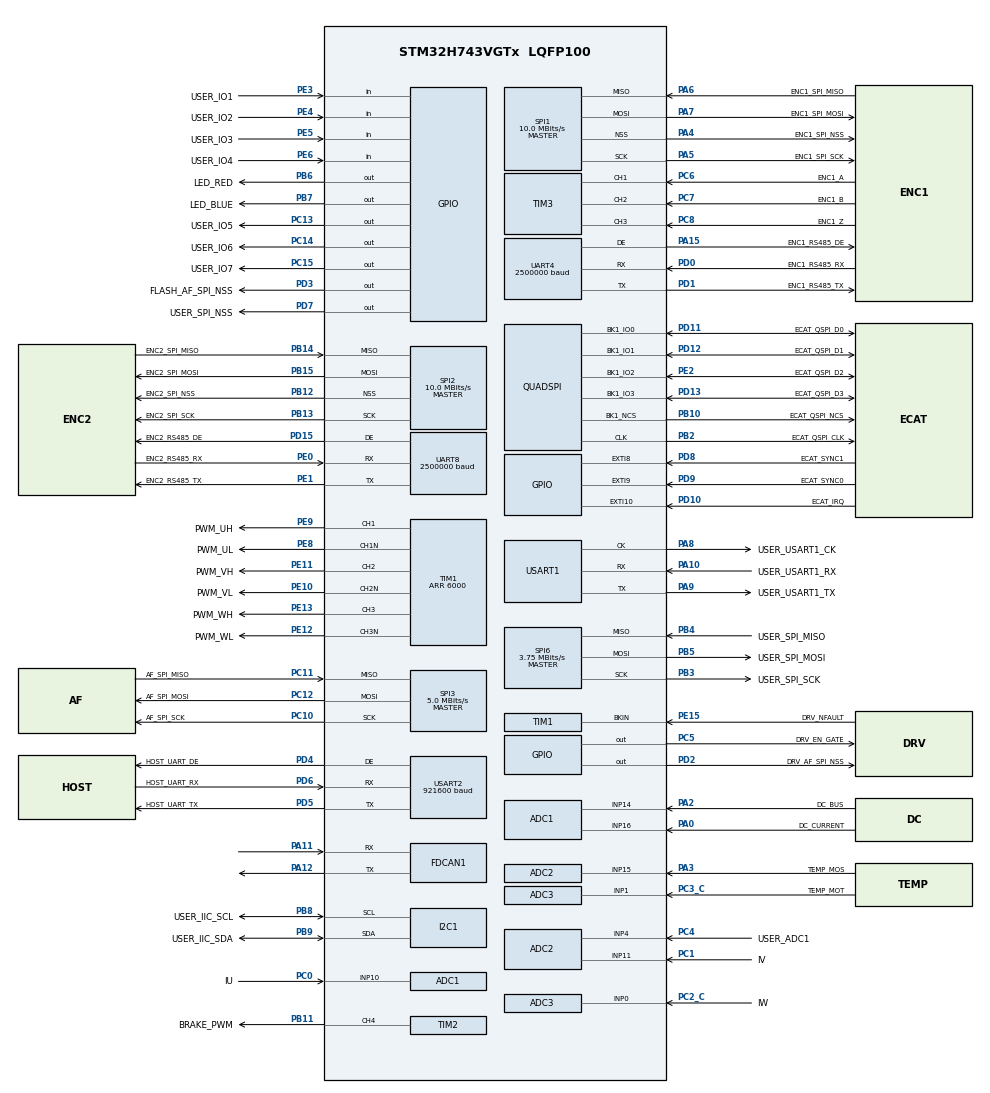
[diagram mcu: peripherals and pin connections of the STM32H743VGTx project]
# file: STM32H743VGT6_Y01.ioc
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ADC1.Channel-3\#ChannelRegularConversion=ADC_CHANNEL_14
ADC1.Channel-5\#ChannelRegularConversion=ADC_CHANNEL_16
ADC1.ClockPrescaler=ADC_CLOCK_ASYNC_DIV1
ADC1.ContinuousConvMode=ENABLE
ADC1.ConversionDataManagement=ADC_CONVERSIONDATA_DMA_CIRCULAR
ADC1.DiscontinuousConvMode=DISABLE
ADC1.EnableInjectedConversion=ENABLE
ADC1.ExternalTrigInjecConv=ADC_EXTERNALTRIGINJEC_T1_TRGO
ADC1.InjNumberOfConversion=1
ADC1.InjectedChannel-4\#ChannelInjectedConversion=ADC_CHANNEL_10
ADC1.InjectedOffsetNumber-4\#ChannelInjectedConversion=ADC_OFFSET_NONE
ADC1.InjectedOffsetSaturation-4\#ChannelInjectedConversion=DISABLE
ADC1.InjectedOffsetSignedSaturation-4\#ChannelInjectedConversion=DISABLE
ADC1.InjectedRank-4\#ChannelInjectedConversion=1
ADC1.InjectedSamplingTime-4\#ChannelInjectedConversion=ADC_SAMPLETIME_2CYCLES_5
ADC1.NbrOfConversion=2
ADC1.NbrOfConversionFlag=1
ADC1.NbrOfDiscConversion=2
ADC1.OffsetNumber-3\#ChannelRegularConversion=ADC_OFFSET_NONE
ADC1.OffsetNumber-5\#ChannelRegularConversion=ADC_OFFSET_NONE
ADC1.OffsetSignedSaturation-3\#ChannelRegularConversion=DISABLE
ADC1.OffsetSignedSaturation-5\#ChannelRegularConversion=DISABLE
ADC1.Rank-3\#ChannelRegularConversion=1
ADC1.Rank-5\#ChannelRegularConversion=2
ADC1.SamplingTime-3\#ChannelRegularConversion=ADC_SAMPLETIME_2CYCLES_5
ADC1.SamplingTime-5\#ChannelRegularConversion=ADC_SAMPLETIME_2CYCLES_5
ADC1.master=1
ADC2.Channel-2\#ChannelRegularConversion=ADC_CHANNEL_15
ADC2.Channel-3\#ChannelRegularConversion=ADC_CHANNEL_4
ADC2.ContinuousConvMode=ENABLE
ADC2.ConversionDataManagement=ADC_CONVERSIONDATA_DMA_CIRCULAR
ADC2.DiscontinuousConvMode=DISABLE
ADC2.EnableInjectedConversion=ENABLE
ADC2.ExternalTrigInjecConv=ADC_EXTERNALTRIGINJEC_T1_TRGO
ADC2.InjNumberOfConversion=1
ADC2.InjectedChannel-4\#ChannelInjectedConversion=ADC_CHANNEL_11
ADC2.InjectedOffsetNumber-4\#ChannelInjectedConversion=ADC_OFFSET_NONE
ADC2.InjectedOffsetSaturation-4\#ChannelInjectedConversion=DISABLE
ADC2.InjectedOffsetSignedSaturation-4\#ChannelInjectedConversion=DISABLE
ADC2.InjectedRank-4\#ChannelInjectedConversion=1
ADC2.InjectedSamplingTime-4\#ChannelInjectedConversion=ADC_SAMPLETIME_2CYCLES_5
ADC2.NbrOfConversion=2
ADC2.NbrOfConversionFlag=1
ADC2.NbrOfDiscConversion=2
ADC2.OffsetNumber-2\#ChannelRegularConversion=ADC_OFFSET_NONE
ADC2.OffsetNumber-3\#ChannelRegularConversion=ADC_OFFSET_NONE
ADC2.OffsetSignedSaturation-2\#ChannelRegularConversion=DISABLE
ADC2.OffsetSignedSaturation-3\#ChannelRegularConversion=DISABLE
ADC2.Rank-2\#ChannelRegularConversion=1
ADC2.Rank-3\#ChannelRegularConversion=2
ADC2.SamplingTime-2\#ChannelRegularConversion=ADC_SAMPLETIME_387CYCLES_5
ADC2.SamplingTime-3\#ChannelRegularConversion=ADC_SAMPLETIME_2CYCLES_5
ADC3.Channel-3\#ChannelRegularConversion=ADC_CHANNEL_TEMPSENSOR
ADC3.Channel-4\#ChannelRegularConversion=ADC_CHANNEL_1
ADC3.ClockPrescaler=ADC_CLOCK_ASYNC_DIV1
ADC3.ContinuousConvMode=ENABLE
ADC3.ConversionDataManagement=ADC_CONVERSIONDATA_DMA_CIRCULAR
ADC3.DiscontinuousConvMode=DISABLE
ADC3.EnableInjectedConversion=ENABLE
ADC3.ExternalTrigInjecConv=ADC_EXTERNALTRIGINJEC_T1_TRGO
ADC3.InjNumberOfConversion=1
ADC3.InjectedChannel-5\#ChannelInjectedConversion=ADC_CHANNEL_0
ADC3.InjectedOffsetNumber-5\#ChannelInjectedConversion=ADC_OFFSET_NONE
ADC3.InjectedOffsetSaturation-5\#ChannelInjectedConversion=DISABLE
ADC3.InjectedOffsetSignedSaturation-5\#ChannelInjectedConversion=DISABLE
ADC3.InjectedRank-5\#ChannelInjectedConversion=1
ADC3.InjectedSamplingTime-5\#ChannelInjectedConversion=ADC_SAMPLETIME_2CYCLES_5
ADC3.NbrOfConversion=2
ADC3.NbrOfConversionFlag=1
ADC3.NbrOfDiscConversion=2
ADC3.OffsetNumber-3\#ChannelRegularConversion=ADC_OFFSET_NONE
ADC3.OffsetNumber-4\#ChannelRegularConversion=ADC_OFFSET_NONE
ADC3.OffsetSignedSaturation-3\#ChannelRegularConversion=DISABLE
ADC3.OffsetSignedSaturation-4\#ChannelRegularConversion=DISABLE
ADC3.Rank-3\#ChannelRegularConversion=1
ADC3.Rank-4\#ChannelRegularConversion=2
ADC3.SamplingTime-3\#ChannelRegularConversion=ADC_SAMPLETIME_810CYCLES_5
ADC3.SamplingTime-4\#ChannelRegularConversion=ADC_SAMPLETIME_387CYCLES_5
CORTEX_M7.default_mode_Activation=0
CRC.InputDataFormat=CRC_INPUTDATA_FORMAT_WORDS
Dma.ADC1.10.Direction=DMA_PERIPH_TO_MEMORY
Dma.ADC1.10.EventEnable=DISABLE
Dma.ADC1.10.FIFOMode=DMA_FIFOMODE_DISABLE
Dma.ADC1.10.Instance=DMA2_Stream4
Dma.ADC1.10.MemDataAlignment=DMA_MDATAALIGN_HALFWORD
Dma.ADC1.10.MemInc=DMA_MINC_ENABLE
Dma.ADC1.10.Mode=DMA_CIRCULAR
Dma.ADC1.10.PeriphDataAlignment=DMA_PDATAALIGN_HALFWORD
Dma.ADC1.10.PeriphInc=DMA_PINC_DISABLE
Dma.ADC1.10.Polarity=HAL_DMAMUX_REQ_GEN_RISING
Dma.ADC1.10.Priority=DMA_PRIORITY_MEDIUM
Dma.ADC1.10.RequestNumber=1
Dma.ADC1.10.SignalID=NONE
Dma.ADC1.10.SyncEnable=DISABLE
Dma.ADC1.10.SyncPolarity=HAL_DMAMUX_SYNC_NO_EVENT
Dma.ADC1.10.SyncRequestNumber=1
Dma.ADC1.10.SyncSignalID=NONE
Dma.ADC2.11.Direction=DMA_PERIPH_TO_MEMORY
Dma.ADC2.11.EventEnable=DISABLE
Dma.ADC2.11.FIFOMode=DMA_FIFOMODE_DISABLE
Dma.ADC2.11.Instance=DMA2_Stream5
Dma.ADC2.11.MemDataAlignment=DMA_MDATAALIGN_HALFWORD
Dma.ADC2.11.MemInc=DMA_MINC_ENABLE
Dma.ADC2.11.Mode=DMA_CIRCULAR
Dma.ADC2.11.PeriphDataAlignment=DMA_PDATAALIGN_HALFWORD
Dma.ADC2.11.PeriphInc=DMA_PINC_DISABLE
Dma.ADC2.11.Polarity=HAL_DMAMUX_REQ_GEN_RISING
Dma.ADC2.11.Priority=DMA_PRIORITY_MEDIUM
Dma.ADC2.11.RequestNumber=1
Dma.ADC2.11.SignalID=NONE
Dma.ADC2.11.SyncEnable=DISABLE
Dma.ADC2.11.SyncPolarity=HAL_DMAMUX_SYNC_NO_EVENT
Dma.ADC2.11.SyncRequestNumber=1
Dma.ADC2.11.SyncSignalID=NONE
Dma.ADC3.12.Direction=DMA_PERIPH_TO_MEMORY
Dma.ADC3.12.EventEnable=DISABLE
Dma.ADC3.12.FIFOMode=DMA_FIFOMODE_DISABLE
Dma.ADC3.12.Instance=DMA2_Stream6
Dma.ADC3.12.MemDataAlignment=DMA_MDATAALIGN_HALFWORD
Dma.ADC3.12.MemInc=DMA_MINC_ENABLE
Dma.ADC3.12.Mode=DMA_CIRCULAR
Dma.ADC3.12.PeriphDataAlignment=DMA_PDATAALIGN_HALFWORD
Dma.ADC3.12.PeriphInc=DMA_PINC_DISABLE
Dma.ADC3.12.Polarity=HAL_DMAMUX_REQ_GEN_RISING
Dma.ADC3.12.Priority=DMA_PRIORITY_MEDIUM
Dma.ADC3.12.RequestNumber=1
Dma.ADC3.12.SignalID=NONE
Dma.ADC3.12.SyncEnable=DISABLE
Dma.ADC3.12.SyncPolarity=HAL_DMAMUX_SYNC_NO_EVENT
Dma.ADC3.12.SyncRequestNumber=1
Dma.ADC3.12.SyncSignalID=NONE
Dma.Request0=UART4_RX
Dma.Request1=UART4_TX
Dma.Request10=ADC1
Dma.Request11=ADC2
Dma.Request12=ADC3
Dma.Request2=SPI1_RX
Dma.Request3=SPI1_TX
Dma.Request4=UART8_RX
Dma.Request5=UART8_TX
Dma.Request6=SPI2_RX
Dma.Request7=SPI2_TX
Dma.Request8=USART2_RX
Dma.Request9=USART2_TX
Dma.SPI1_RX.2.Direction=DMA_PERIPH_TO_MEMORY
Dma.SPI1_RX.2.EventEnable=DISABLE
Dma.SPI1_RX.2.FIFOMode=DMA_FIFOMODE_DISABLE
Dma.SPI1_RX.2.Instance=DMA1_Stream2
Dma.SPI1_RX.2.MemDataAlignment=DMA_MDATAALIGN_BYTE
Dma.SPI1_RX.2.MemInc=DMA_MINC_ENABLE
Dma.SPI1_RX.2.Mode=DMA_NORMAL
Dma.SPI1_RX.2.PeriphDataAlignment=DMA_PDATAALIGN_BYTE
Dma.SPI1_RX.2.PeriphInc=DMA_PINC_DISABLE
Dma.SPI1_RX.2.Polarity=HAL_DMAMUX_REQ_GEN_RISING
Dma.SPI1_RX.2.Priority=DMA_PRIORITY_VERY_HIGH
Dma.SPI1_RX.2.RequestNumber=1
Dma.SPI1_RX.2.SignalID=NONE
Dma.SPI1_RX.2.SyncEnable=DISABLE
Dma.SPI1_RX.2.SyncPolarity=HAL_DMAMUX_SYNC_NO_EVENT
Dma.SPI1_RX.2.SyncRequestNumber=1
Dma.SPI1_RX.2.SyncSignalID=NONE
Dma.SPI1_TX.3.Direction=DMA_MEMORY_TO_PERIPH
Dma.SPI1_TX.3.EventEnable=DISABLE
Dma.SPI1_TX.3.FIFOMode=DMA_FIFOMODE_DISABLE
Dma.SPI1_TX.3.Instance=DMA1_Stream3
Dma.SPI1_TX.3.MemDataAlignment=DMA_MDATAALIGN_BYTE
Dma.SPI1_TX.3.MemInc=DMA_MINC_ENABLE
Dma.SPI1_TX.3.Mode=DMA_NORMAL
Dma.SPI1_TX.3.PeriphDataAlignment=DMA_PDATAALIGN_BYTE
Dma.SPI1_TX.3.PeriphInc=DMA_PINC_DISABLE
Dma.SPI1_TX.3.Polarity=HAL_DMAMUX_REQ_GEN_RISING
Dma.SPI1_TX.3.Priority=DMA_PRIORITY_VERY_HIGH
Dma.SPI1_TX.3.RequestNumber=1
Dma.SPI1_TX.3.SignalID=NONE
Dma.SPI1_TX.3.SyncEnable=DISABLE
Dma.SPI1_TX.3.SyncPolarity=HAL_DMAMUX_SYNC_NO_EVENT
Dma.SPI1_TX.3.SyncRequestNumber=1
Dma.SPI1_TX.3.SyncSignalID=NONE
Dma.SPI2_RX.6.Direction=DMA_PERIPH_TO_MEMORY
Dma.SPI2_RX.6.EventEnable=DISABLE
Dma.SPI2_RX.6.FIFOMode=DMA_FIFOMODE_DISABLE
Dma.SPI2_RX.6.Instance=DMA2_Stream2
Dma.SPI2_RX.6.MemDataAlignment=DMA_MDATAALIGN_BYTE
Dma.SPI2_RX.6.MemInc=DMA_MINC_ENABLE
Dma.SPI2_RX.6.Mode=DMA_NORMAL
Dma.SPI2_RX.6.PeriphDataAlignment=DMA_PDATAALIGN_BYTE
Dma.SPI2_RX.6.PeriphInc=DMA_PINC_DISABLE
Dma.SPI2_RX.6.Polarity=HAL_DMAMUX_REQ_GEN_RISING
Dma.SPI2_RX.6.Priority=DMA_PRIORITY_VERY_HIGH
Dma.SPI2_RX.6.RequestNumber=1
Dma.SPI2_RX.6.SignalID=NONE
Dma.SPI2_RX.6.SyncEnable=DISABLE
Dma.SPI2_RX.6.SyncPolarity=HAL_DMAMUX_SYNC_NO_EVENT
Dma.SPI2_RX.6.SyncRequestNumber=1
Dma.SPI2_RX.6.SyncSignalID=NONE
Dma.SPI2_TX.7.Direction=DMA_MEMORY_TO_PERIPH
Dma.SPI2_TX.7.EventEnable=DISABLE
Dma.SPI2_TX.7.FIFOMode=DMA_FIFOMODE_DISABLE
Dma.SPI2_TX.7.Instance=DMA2_Stream3
Dma.SPI2_TX.7.MemDataAlignment=DMA_MDATAALIGN_BYTE
Dma.SPI2_TX.7.MemInc=DMA_MINC_ENABLE
Dma.SPI2_TX.7.Mode=DMA_NORMAL
Dma.SPI2_TX.7.PeriphDataAlignment=DMA_PDATAALIGN_BYTE
Dma.SPI2_TX.7.PeriphInc=DMA_PINC_DISABLE
Dma.SPI2_TX.7.Polarity=HAL_DMAMUX_REQ_GEN_RISING
Dma.SPI2_TX.7.Priority=DMA_PRIORITY_VERY_HIGH
Dma.SPI2_TX.7.RequestNumber=1
Dma.SPI2_TX.7.SignalID=NONE
Dma.SPI2_TX.7.SyncEnable=DISABLE
Dma.SPI2_TX.7.SyncPolarity=HAL_DMAMUX_SYNC_NO_EVENT
Dma.SPI2_TX.7.SyncRequestNumber=1
Dma.SPI2_TX.7.SyncSignalID=NONE
Dma.UART4_RX.0.Direction=DMA_PERIPH_TO_MEMORY
Dma.UART4_RX.0.EventEnable=DISABLE
Dma.UART4_RX.0.FIFOMode=DMA_FIFOMODE_DISABLE
Dma.UART4_RX.0.Instance=DMA1_Stream0
Dma.UART4_RX.0.MemDataAlignment=DMA_MDATAALIGN_BYTE
Dma.UART4_RX.0.MemInc=DMA_MINC_ENABLE
Dma.UART4_RX.0.Mode=DMA_NORMAL
Dma.UART4_RX.0.PeriphDataAlignment=DMA_PDATAALIGN_BYTE
Dma.UART4_RX.0.PeriphInc=DMA_PINC_DISABLE
Dma.UART4_RX.0.Polarity=HAL_DMAMUX_REQ_GEN_RISING
Dma.UART4_RX.0.Priority=DMA_PRIORITY_VERY_HIGH
Dma.UART4_RX.0.RequestNumber=1
Dma.UART4_RX.0.SignalID=NONE
Dma.UART4_RX.0.SyncEnable=DISABLE
Dma.UART4_RX.0.SyncPolarity=HAL_DMAMUX_SYNC_NO_EVENT
Dma.UART4_RX.0.SyncRequestNumber=1
Dma.UART4_RX.0.SyncSignalID=NONE
Dma.UART4_TX.1.Direction=DMA_MEMORY_TO_PERIPH
Dma.UART4_TX.1.EventEnable=DISABLE
Dma.UART4_TX.1.FIFOMode=DMA_FIFOMODE_DISABLE
Dma.UART4_TX.1.Instance=DMA1_Stream1
Dma.UART4_TX.1.MemDataAlignment=DMA_MDATAALIGN_BYTE
Dma.UART4_TX.1.MemInc=DMA_MINC_ENABLE
Dma.UART4_TX.1.Mode=DMA_NORMAL
Dma.UART4_TX.1.PeriphDataAlignment=DMA_PDATAALIGN_BYTE
Dma.UART4_TX.1.PeriphInc=DMA_PINC_DISABLE
Dma.UART4_TX.1.Polarity=HAL_DMAMUX_REQ_GEN_RISING
Dma.UART4_TX.1.Priority=DMA_PRIORITY_VERY_HIGH
Dma.UART4_TX.1.RequestNumber=1
Dma.UART4_TX.1.SignalID=NONE
Dma.UART4_TX.1.SyncEnable=DISABLE
Dma.UART4_TX.1.SyncPolarity=HAL_DMAMUX_SYNC_NO_EVENT
Dma.UART4_TX.1.SyncRequestNumber=1
Dma.UART4_TX.1.SyncSignalID=NONE
Dma.UART8_RX.4.Direction=DMA_PERIPH_TO_MEMORY
Dma.UART8_RX.4.EventEnable=DISABLE
Dma.UART8_RX.4.FIFOMode=DMA_FIFOMODE_DISABLE
Dma.UART8_RX.4.Instance=DMA2_Stream0
Dma.UART8_RX.4.MemDataAlignment=DMA_MDATAALIGN_BYTE
Dma.UART8_RX.4.MemInc=DMA_MINC_ENABLE
Dma.UART8_RX.4.Mode=DMA_NORMAL
Dma.UART8_RX.4.PeriphDataAlignment=DMA_PDATAALIGN_BYTE
Dma.UART8_RX.4.PeriphInc=DMA_PINC_DISABLE
Dma.UART8_RX.4.Polarity=HAL_DMAMUX_REQ_GEN_RISING
Dma.UART8_RX.4.Priority=DMA_PRIORITY_VERY_HIGH
Dma.UART8_RX.4.RequestNumber=1
Dma.UART8_RX.4.SignalID=NONE
Dma.UART8_RX.4.SyncEnable=DISABLE
Dma.UART8_RX.4.SyncPolarity=HAL_DMAMUX_SYNC_NO_EVENT
Dma.UART8_RX.4.SyncRequestNumber=1
Dma.UART8_RX.4.SyncSignalID=NONE
Dma.UART8_TX.5.Direction=DMA_MEMORY_TO_PERIPH
Dma.UART8_TX.5.EventEnable=DISABLE
Dma.UART8_TX.5.FIFOMode=DMA_FIFOMODE_DISABLE
Dma.UART8_TX.5.Instance=DMA2_Stream1
Dma.UART8_TX.5.MemDataAlignment=DMA_MDATAALIGN_BYTE
Dma.UART8_TX.5.MemInc=DMA_MINC_ENABLE
Dma.UART8_TX.5.Mode=DMA_NORMAL
Dma.UART8_TX.5.PeriphDataAlignment=DMA_PDATAALIGN_BYTE
Dma.UART8_TX.5.PeriphInc=DMA_PINC_DISABLE
Dma.UART8_TX.5.Polarity=HAL_DMAMUX_REQ_GEN_RISING
Dma.UART8_TX.5.Priority=DMA_PRIORITY_VERY_HIGH
Dma.UART8_TX.5.RequestNumber=1
Dma.UART8_TX.5.SignalID=NONE
Dma.UART8_TX.5.SyncEnable=DISABLE
Dma.UART8_TX.5.SyncPolarity=HAL_DMAMUX_SYNC_NO_EVENT
Dma.UART8_TX.5.SyncRequestNumber=1
Dma.UART8_TX.5.SyncSignalID=NONE
Dma.USART2_RX.8.Direction=DMA_PERIPH_TO_MEMORY
Dma.USART2_RX.8.EventEnable=DISABLE
Dma.USART2_RX.8.FIFOMode=DMA_FIFOMODE_DISABLE
Dma.USART2_RX.8.Instance=DMA1_Stream4
Dma.USART2_RX.8.MemDataAlignment=DMA_MDATAALIGN_BYTE
Dma.USART2_RX.8.MemInc=DMA_MINC_ENABLE
Dma.USART2_RX.8.Mode=DMA_NORMAL
Dma.USART2_RX.8.PeriphDataAlignment=DMA_PDATAALIGN_BYTE
Dma.USART2_RX.8.PeriphInc=DMA_PINC_DISABLE
Dma.USART2_RX.8.Polarity=HAL_DMAMUX_REQ_GEN_RISING
Dma.USART2_RX.8.Priority=DMA_PRIORITY_LOW
Dma.USART2_RX.8.RequestNumber=1
Dma.USART2_RX.8.SignalID=NONE
Dma.USART2_RX.8.SyncEnable=DISABLE
Dma.USART2_RX.8.SyncPolarity=HAL_DMAMUX_SYNC_NO_EVENT
Dma.USART2_RX.8.SyncRequestNumber=1
Dma.USART2_RX.8.SyncSignalID=NONE
Dma.USART2_TX.9.Direction=DMA_MEMORY_TO_PERIPH
Dma.USART2_TX.9.EventEnable=DISABLE
Dma.USART2_TX.9.FIFOMode=DMA_FIFOMODE_DISABLE
Dma.USART2_TX.9.Instance=DMA1_Stream5
Dma.USART2_TX.9.MemDataAlignment=DMA_MDATAALIGN_BYTE
Dma.USART2_TX.9.MemInc=DMA_MINC_ENABLE
Dma.USART2_TX.9.Mode=DMA_NORMAL
Dma.USART2_TX.9.PeriphDataAlignment=DMA_PDATAALIGN_BYTE
Dma.USART2_TX.9.PeriphInc=DMA_PINC_DISABLE
Dma.USART2_TX.9.Polarity=HAL_DMAMUX_REQ_GEN_RISING
Dma.USART2_TX.9.Priority=DMA_PRIORITY_LOW
Dma.USART2_TX.9.RequestNumber=1
Dma.USART2_TX.9.SignalID=NONE
Dma.USART2_TX.9.SyncEnable=DISABLE
Dma.USART2_TX.9.SyncPolarity=HAL_DMAMUX_SYNC_NO_EVENT
Dma.USART2_TX.9.SyncRequestNumber=1
Dma.USART2_TX.9.SyncSignalID=NONE
FDCAN1.AutoRetransmission=ENABLE
FDCAN1.CalculateBaudRateNominal=1000000
FDCAN1.CalculateTimeBitNominal=1000
FDCAN1.CalculateTimeQuantumNominal=100.0
FDCAN1.DataPrescaler=8
FDCAN1.DataTimeSeg1=7
FDCAN1.DataTimeSeg2=2
FDCAN1.ExtFiltersNbr=64
FDCAN1.FrameFormat=FDCAN_FRAME_FD_BRS
FDCAN1.NominalPrescaler=8
FDCAN1.NominalSyncJumpWidth=2
FDCAN1.NominalTimeSeg1=7
FDCAN1.ProtocolException=ENABLE
FDCAN1.RxBufferSize=FDCAN_DATA_BYTES_64
FDCAN1.RxBuffersNbr=8
FDCAN1.RxFifo0ElmtSize=FDCAN_DATA_BYTES_64
FDCAN1.RxFifo0ElmtsNbr=32
FDCAN1.RxFifo1ElmtSize=FDCAN_DATA_BYTES_64
FDCAN1.RxFifo1ElmtsNbr=32
FDCAN1.StdFiltersNbr=128
FDCAN1.TransmitPause=ENABLE
FDCAN1.TxElmtSize=FDCAN_DATA_BYTES_64
FDCAN1.TxFifoQueueElmtsNbr=32
I2C1.I2C_Fall_Time=10
I2C1.I2C_Rise_Time=100
I2C1.Speed=100
I2C1.Timing=0x40805E8A
Mcu.Family=STM32H7
Mcu.Name=STM32H743VGTx
Mcu.Package=LQFP100
NVIC.ADC_IRQn=true\:2\:0\:true\:false\:true\:true\:true\:true
NVIC.DMA1_Stream0_IRQn=true\:1\:0\:true\:false\:true\:false\:true\:true
NVIC.DMA1_Stream1_IRQn=true\:1\:0\:true\:false\:true\:false\:true\:true
NVIC.DMA1_Stream2_IRQn=true\:1\:0\:true\:false\:true\:false\:true\:true
NVIC.DMA1_Stream3_IRQn=true\:1\:0\:true\:false\:true\:false\:true\:true
NVIC.DMA1_Stream4_IRQn=true\:7\:0\:true\:false\:true\:false\:true\:true
NVIC.DMA1_Stream5_IRQn=true\:7\:0\:true\:false\:true\:false\:true\:true
NVIC.DMA2_Stream0_IRQn=true\:1\:0\:true\:false\:true\:false\:true\:true
NVIC.DMA2_Stream1_IRQn=true\:1\:0\:true\:false\:true\:false\:true\:true
NVIC.DMA2_Stream2_IRQn=true\:1\:0\:true\:false\:true\:false\:true\:true
NVIC.DMA2_Stream3_IRQn=true\:1\:0\:true\:false\:true\:false\:true\:true
NVIC.EXTI15_10_IRQn=true\:2\:0\:true\:false\:true\:true\:true\:false
NVIC.EXTI9_5_IRQn=true\:1\:0\:true\:false\:true\:true\:true\:false
NVIC.FDCAN1_IT0_IRQn=true\:5\:0\:true\:false\:true\:true\:true\:true
NVIC.FDCAN1_IT1_IRQn=true\:5\:0\:true\:false\:true\:true\:true\:true
NVIC.PriorityGroup=NVIC_PRIORITYGROUP_4
NVIC.SPI1_IRQn=true\:0\:0\:false\:false\:true\:false\:true\:true
NVIC.SPI2_IRQn=true\:0\:0\:false\:false\:true\:false\:true\:true
NVIC.TIM1_BRK_IRQn=true\:0\:0\:false\:false\:true\:true\:true\:true
NVIC.TIM2_IRQn=true\:9\:0\:true\:false\:true\:true\:true\:true
NVIC.TIM3_IRQn=true\:2\:0\:true\:false\:true\:true\:true\:true
NVIC.TIM5_IRQn=true\:3\:0\:true\:false\:false\:true\:true\:true
NVIC.TIM6_DAC_IRQn=true\:4\:0\:true\:false\:true\:true\:true\:true
NVIC.TIM7_IRQn=true\:4\:0\:true\:false\:true\:true\:true\:true
NVIC.TIM8_UP_TIM13_IRQn=true\:5\:0\:true\:false\:true\:true\:true\:true
NVIC.USART2_IRQn=true\:8\:0\:true\:false\:false\:true\:false\:true
PA0.GPIO_Label=DC_CURRENT
PA0.Mode=IN16-Single-Ended
PA0.Signal=ADC1_INP16
PA10.GPIO_Label=USER_USART1_RX
PA10.GPIO_Speed=GPIO_SPEED_FREQ_VERY_HIGH
PA10.Mode=Synchronous
PA10.PinAttribute=Free
PA10.Signal=USART1_RX
PA11.GPIO_Speed=GPIO_SPEED_FREQ_VERY_HIGH
PA11.Mode=FDCAN_Activate
PA11.Signal=FDCAN1_RX
PA12.GPIO_Speed=GPIO_SPEED_FREQ_VERY_HIGH
PA12.Mode=FDCAN_Activate
PA12.Signal=FDCAN1_TX
PA13\ (JTMS/SWDIO).GPIO_Label=SWDIO
PA13\ (JTMS/SWDIO).Mode=Serial_Wire
PA13\ (JTMS/SWDIO).Signal=DEBUG_JTMS-SWDIO
PA14\ (JTCK/SWCLK).GPIO_Label=SWCLK
PA14\ (JTCK/SWCLK).Mode=Serial_Wire
PA14\ (JTCK/SWCLK).Signal=DEBUG_JTCK-SWCLK
PA15\ (JTDI).GPIO_Label=ENC1_RS485_DE
PA15\ (JTDI).GPIO_Speed=GPIO_SPEED_FREQ_VERY_HIGH
PA15\ (JTDI).Mode=Hardware Flow Control (RS485)
PA15\ (JTDI).Signal=UART4_DE
PA2.GPIO_Label=DC_BUS
PA2.Signal=ADCx_INP14
PA3.GPIO_Label=TEMP_MOS
PA3.Signal=ADCx_INP15
PA4.GPIO_Label=ENC1_SPI_NSS
PA4.GPIO_Speed=GPIO_SPEED_FREQ_VERY_HIGH
PA4.Mode=NSS_Signal_Hard_Output
PA4.Signal=SPI1_NSS
PA5.GPIO_Label=ENC1_SPI_SCK
PA5.GPIO_Speed=GPIO_SPEED_FREQ_VERY_HIGH
PA5.Mode=Full_Duplex_Master
PA5.Signal=SPI1_SCK
PA6.GPIO_Label=ENC1_SPI_MISO
PA6.GPIO_Speed=GPIO_SPEED_FREQ_VERY_HIGH
PA6.Mode=Full_Duplex_Master
PA6.Signal=SPI1_MISO
PA7.GPIO_Label=ENC1_SPI_MOSI
PA7.GPIO_Speed=GPIO_SPEED_FREQ_VERY_HIGH
PA7.Mode=Full_Duplex_Master
PA7.Signal=SPI1_MOSI
PA8.GPIO_Label=USER_USART1_CK
PA8.GPIO_Speed=GPIO_SPEED_FREQ_VERY_HIGH
PA8.Mode=Synchronous
PA8.PinAttribute=Free
PA8.Signal=USART1_CK
PA9.GPIO_Label=USER_USART1_TX
PA9.GPIO_Speed=GPIO_SPEED_FREQ_VERY_HIGH
PA9.Mode=Synchronous
PA9.PinAttribute=Free
PA9.Signal=USART1_TX
PB10.GPIO_Label=ECAT_QSPI_NCS
PB10.GPIO_Speed=GPIO_SPEED_FREQ_VERY_HIGH
PB10.Mode=Single Bank 1
PB10.PinAttribute=Free
PB10.Signal=QUADSPI_BK1_NCS
PB11.GPIO_Label=BRAKE_PWM
PB11.GPIO_Speed=GPIO_SPEED_FREQ_VERY_HIGH
PB11.PinAttribute=Free
PB11.Signal=S_TIM2_CH4
PB12.GPIO_Label=ENC2_SPI_NSS
PB12.GPIO_Speed=GPIO_SPEED_FREQ_VERY_HIGH
PB12.Mode=NSS_Signal_Hard_Output
PB12.PinAttribute=Free
PB12.Signal=SPI2_NSS
PB13.GPIO_Label=ENC2_SPI_SCK
PB13.GPIO_Speed=GPIO_SPEED_FREQ_VERY_HIGH
PB13.Mode=Full_Duplex_Master
PB13.PinAttribute=Free
PB13.Signal=SPI2_SCK
PB14.GPIO_Label=ENC2_SPI_MISO
PB14.GPIO_Speed=GPIO_SPEED_FREQ_VERY_HIGH
PB14.Mode=Full_Duplex_Master
PB14.PinAttribute=Free
PB14.Signal=SPI2_MISO
PB15.GPIO_Label=ENC2_SPI_MOSI
PB15.GPIO_Speed=GPIO_SPEED_FREQ_VERY_HIGH
PB15.Mode=Full_Duplex_Master
PB15.PinAttribute=Free
PB15.Signal=SPI2_MOSI
PB2.GPIO_Label=ECAT_QSPI_CLK
PB2.GPIO_Speed=GPIO_SPEED_FREQ_VERY_HIGH
PB2.Mode=Single Bank 1
PB2.Signal=QUADSPI_CLK
PB3\ (JTDO/TRACESWO).GPIO_Label=USER_SPI_SCK
PB3\ (JTDO/TRACESWO).GPIO_Speed=GPIO_SPEED_FREQ_VERY_HIGH
PB3\ (JTDO/TRACESWO).Mode=Full_Duplex_Master
PB3\ (JTDO/TRACESWO).Signal=SPI6_SCK
PB4\ (NJTRST).GPIO_Label=USER_SPI_MISO
PB4\ (NJTRST).GPIO_Speed=GPIO_SPEED_FREQ_VERY_HIGH
PB4\ (NJTRST).Mode=Full_Duplex_Master
PB4\ (NJTRST).PinAttribute=Free
PB4\ (NJTRST).Signal=SPI6_MISO
PB5.GPIO_Label=USER_SPI_MOSI
PB5.GPIO_Speed=GPIO_SPEED_FREQ_VERY_HIGH
PB5.Mode=Full_Duplex_Master
PB5.PinAttribute=Free
PB5.Signal=SPI6_MOSI
PB6.GPIO_Label=LED_RED
PB6.PinAttribute=Free
PB6.Signal=GPIO_Output
PB7.GPIO_Label=LED_BLUE
PB7.PinAttribute=Free
PB7.Signal=GPIO_Output
PB8.GPIO_Label=USER_IIC_SCL
PB8.GPIO_Speed=GPIO_SPEED_FREQ_MEDIUM
PB8.Mode=I2C
PB8.PinAttribute=Free
PB8.Signal=I2C1_SCL
PB9.GPIO_Label=USER_IIC_SDA
PB9.GPIO_Speed=GPIO_SPEED_FREQ_MEDIUM
PB9.Mode=I2C
PB9.PinAttribute=Free
PB9.Signal=I2C1_SDA
PC0.GPIO_Label=IU
PC0.Signal=ADCx_INP10
PC1.GPIO_Label=IV
PC1.Signal=ADCx_INP11
PC10.GPIO_Label=AF_SPI_SCK
PC10.GPIO_Speed=GPIO_SPEED_FREQ_VERY_HIGH
PC10.Mode=Full_Duplex_Master
PC10.Signal=SPI3_SCK
PC11.GPIO_Label=AF_SPI_MISO
PC11.GPIO_Speed=GPIO_SPEED_FREQ_VERY_HIGH
PC11.Mode=Full_Duplex_Master
PC11.Signal=SPI3_MISO
PC12.GPIO_Label=AF_SPI_MOSI
PC12.GPIO_Speed=GPIO_SPEED_FREQ_VERY_HIGH
PC12.Mode=Full_Duplex_Master
PC12.Signal=SPI3_MOSI
PC13.GPIO_Label=USER_IO5
PC13.GPIO_Speed=GPIO_SPEED_FREQ_LOW
PC13.Signal=GPIO_Output
PC14-OSC32_IN\ (OSC32_IN).GPIO_Label=USER_IO6
PC14-OSC32_IN\ (OSC32_IN).Signal=GPIO_Output
PC15-OSC32_OUT\ (OSC32_OUT).GPIO_Label=USER_IO7
PC15-OSC32_OUT\ (OSC32_OUT).Signal=GPIO_Output
PC2_C.GPIO_Label=IW
PC2_C.Mode=IN0-Single-Ended
PC2_C.Signal=ADC3_INP0
PC3_C.GPIO_Label=TEMP_MOT
PC3_C.Mode=IN1-Single-Ended
PC3_C.Signal=ADC3_INP1
PC4.GPIO_Label=USER_ADC1
PC4.Signal=ADCx_INP4
PC5.GPIO_Label=DRV_EN_GATE
PC5.GPIO_Speed=GPIO_SPEED_FREQ_VERY_HIGH
PC5.Signal=GPIO_Output
PC6.GPIO_Label=ENC1_A
PC6.GPIO_Speed=GPIO_SPEED_FREQ_HIGH
PC6.PinAttribute=Free
PC6.Signal=S_TIM3_CH1
PC7.GPIO_Label=ENC1_B
PC7.GPIO_Speed=GPIO_SPEED_FREQ_HIGH
PC7.PinAttribute=Free
PC7.Signal=S_TIM3_CH2
PC8.GPIO_Label=ENC1_Z
PC8.GPIO_Speed=GPIO_SPEED_FREQ_HIGH
PC8.PinAttribute=Free
PC8.Signal=S_TIM3_CH3
PD0.GPIO_Label=ENC1_RS485_RX
PD0.GPIO_Speed=GPIO_SPEED_FREQ_VERY_HIGH
PD0.Mode=Asynchronous
PD0.Signal=UART4_RX
PD1.GPIO_Label=ENC1_RS485_TX
PD1.GPIO_Speed=GPIO_SPEED_FREQ_VERY_HIGH
PD1.Mode=Asynchronous
PD1.Signal=UART4_TX
PD10.GPIO_Label=ECAT_IRQ
PD10.GPIO_ModeDefaultEXTI=GPIO_MODE_IT_FALLING
PD10.GPIO_PuPd=GPIO_PULLUP
PD10.PinAttribute=Free
PD10.Signal=GPXTI10
PD11.GPIO_Label=ECAT_QSPI_D0
PD11.GPIO_Speed=GPIO_SPEED_FREQ_VERY_HIGH
PD11.Mode=Single Bank 1
PD11.PinAttribute=Free
PD11.Signal=QUADSPI_BK1_IO0
PD12.GPIO_Label=ECAT_QSPI_D1
PD12.GPIO_Speed=GPIO_SPEED_FREQ_VERY_HIGH
PD12.Mode=Single Bank 1
PD12.PinAttribute=Free
PD12.Signal=QUADSPI_BK1_IO1
PD13.GPIO_Label=ECAT_QSPI_D3
PD13.GPIO_Speed=GPIO_SPEED_FREQ_VERY_HIGH
PD13.Mode=Single Bank 1
PD13.PinAttribute=Free
PD13.Signal=QUADSPI_BK1_IO3
PD15.GPIO_Label=ENC2_RS485_DE
PD15.GPIO_Speed=GPIO_SPEED_FREQ_VERY_HIGH
PD15.Mode=Hardware Flow Control (RS485)
PD15.PinAttribute=Free
PD15.Signal=UART8_DE
PD2.GPIO_Label=DRV_AF_SPI_NSS
PD2.GPIO_PuPd=GPIO_PULLUP
PD2.GPIO_Speed=GPIO_SPEED_FREQ_VERY_HIGH
PD2.PinState=GPIO_PIN_SET
PD2.Signal=GPIO_Output
PD3.GPIO_Label=FLASH_AF_SPI_NSS
PD3.GPIO_PuPd=GPIO_PULLUP
PD3.GPIO_Speed=GPIO_SPEED_FREQ_VERY_HIGH
PD3.PinState=GPIO_PIN_SET
PD3.Signal=GPIO_Output
PD4.GPIO_Label=HOST_UART_DE
PD4.GPIO_Speed=GPIO_SPEED_FREQ_VERY_HIGH
PD4.Mode=Hardware Flow Control (RS485)
PD4.Signal=USART2_DE
PD5.GPIO_Label=HOST_UART_TX
PD5.GPIO_Speed=GPIO_SPEED_FREQ_VERY_HIGH
PD5.Mode=Asynchronous
PD5.Signal=USART2_TX
PD6.GPIO_Label=HOST_UART_RX
PD6.GPIO_Speed=GPIO_SPEED_FREQ_VERY_HIGH
PD6.Mode=Asynchronous
PD6.Signal=USART2_RX
PD7.GPIO_Label=USER_SPI_NSS
PD7.GPIO_PuPd=GPIO_PULLUP
PD7.GPIO_Speed=GPIO_SPEED_FREQ_VERY_HIGH
PD7.PinState=GPIO_PIN_SET
PD7.Signal=GPIO_Output
PD8.GPIO_Label=ECAT_SYNC1
PD8.GPIO_ModeDefaultEXTI=GPIO_MODE_IT_FALLING
PD8.GPIO_PuPd=GPIO_PULLUP
PD8.PinAttribute=Free
PD8.Signal=GPXTI8
PD9.GPIO_Label=ECAT_SYNC0
PD9.GPIO_ModeDefaultEXTI=GPIO_MODE_IT_FALLING
PD9.GPIO_PuPd=GPIO_PULLUP
PD9.PinAttribute=Free
PD9.Signal=GPXTI9
PE0.GPIO_Label=ENC2_RS485_RX
PE0.GPIO_Speed=GPIO_SPEED_FREQ_VERY_HIGH
PE0.Mode=Asynchronous
PE0.PinAttribute=Free
PE0.Signal=UART8_RX
PE1.GPIO_Label=ENC2_RS485_TX
PE1.GPIO_Speed=GPIO_SPEED_FREQ_VERY_HIGH
PE1.Mode=Asynchronous
PE1.PinAttribute=Free
PE1.Signal=UART8_TX
PE10.GPIO_Label=PWM_VL
PE10.GPIO_Speed=GPIO_SPEED_FREQ_HIGH
PE10.Mode=PWM Generation2 CH2 CH2N
PE10.PinAttribute=Free
PE10.Signal=TIM1_CH2N
PE11.GPIO_Label=PWM_VH
PE11.GPIO_Speed=GPIO_SPEED_FREQ_HIGH
PE11.PinAttribute=Free
PE11.Signal=S_TIM1_CH2
PE12.GPIO_Label=PWM_WL
PE12.GPIO_Speed=GPIO_SPEED_FREQ_HIGH
PE12.Mode=PWM Generation3 CH3 CH3N
PE12.PinAttribute=Free
PE12.Signal=TIM1_CH3N
PE13.GPIO_Label=PWM_WH
PE13.GPIO_Speed=GPIO_SPEED_FREQ_HIGH
PE13.PinAttribute=Free
PE13.Signal=S_TIM1_CH3
PE15.GPIO_Label=DRV_NFAULT
PE15.Mode=Activate-Break-Input
PE15.PinAttribute=Free
PE15.Signal=TIM1_BKIN
PE2.GPIO_Label=ECAT_QSPI_D2
PE2.GPIO_Speed=GPIO_SPEED_FREQ_VERY_HIGH
PE2.Mode=Single Bank 1
PE2.Signal=QUADSPI_BK1_IO2
PE3.GPIO_Label=USER_IO1
PE3.GPIO_PuPd=GPIO_PULLUP
PE3.Signal=GPIO_Input
PE4.GPIO_Label=USER_IO2
PE4.GPIO_PuPd=GPIO_PULLUP
PE4.Signal=GPIO_Input
PE5.GPIO_Label=USER_IO3
PE5.GPIO_PuPd=GPIO_PULLUP
PE5.Signal=GPIO_Input
PE6.GPIO_Label=USER_IO4
PE6.GPIO_PuPd=GPIO_PULLUP
PE6.PinAttribute=Free
PE6.Signal=GPIO_Input
PE8.GPIO_Label=PWM_UL
PE8.GPIO_PuPd=GPIO_NOPULL
PE8.GPIO_Speed=GPIO_SPEED_FREQ_HIGH
PE8.Mode=PWM Generation1 CH1 CH1N
PE8.Signal=TIM1_CH1N
PE9.GPIO_Label=PWM_UH
PE9.GPIO_Speed=GPIO_SPEED_FREQ_HIGH
PE9.Signal=S_TIM1_CH1
PH0-OSC_IN\ (PH0).Mode=HSE-External-Clock-Source
PH0-OSC_IN\ (PH0).Signal=RCC_OSC_IN
ProjectManager.HeapSize=0x1000
ProjectManager.StackSize=0x1000
ProjectManager.TargetToolchain=MDK-ARM V5.32
QUADSPI.ClockMode=QSPI_CLOCK_MODE_3
QUADSPI.ClockPrescaler=8-1
QUADSPI.FifoThreshold=4
QUADSPI.FlashSize=15
QUADSPI.SampleShifting=QSPI_SAMPLE_SHIFTING_HALFCYCLE
RCC.ADCFreq_Value=80000000
RCC.APB1Freq_Value=120000000
RCC.APB2Freq_Value=120000000
RCC.APB3Freq_Value=120000000
RCC.APB4Freq_Value=120000000
RCC.CKPERSourceSelection=RCC_CLKPSOURCE_HSE
RCC.CortexFreq_Value=480000000
RCC.D1PPRE=RCC_APB3_DIV2
RCC.D2PPRE1=RCC_APB1_DIV2
RCC.D2PPRE2=RCC_APB2_DIV2
RCC.D3PPRE=RCC_APB4_DIV2
RCC.DIVM1=1
RCC.DIVM2=1
RCC.DIVN1=60
RCC.DIVN2=10
RCC.DIVQ1=6
RCC.FDCANCLockSelection=RCC_FDCANCLKSOURCE_PLL2
RCC.HCLKFreq_Value=240000000
RCC.HPRE=RCC_HCLK_DIV2
RCC.HRTIMCLockSelection=RCC_HRTIM1CLK_CPUCLK
RCC.HSE_VALUE=16000000
RCC.PLL1_VCI_Range-AdvancedSettings=RCC_PLL1VCIRANGE_0
RCC.PLL1_VCO_SEL-AdvancedSettings=RCC_PLL1VCOMEDIUM
RCC.PLL2FRACN=0
RCC.PLL2_VCI_Range-AdvancedSettings=RCC_PLL2VCIRANGE_0
RCC.PLL2_VCO_SEL-AdvancedSettings=RCC_PLL2VCOMEDIUM
RCC.PLL3FRACN=0
RCC.PLL3_VCI_Range-AdvancedSettings=RCC_PLL3VCIRANGE_0
RCC.PLL3_VCO_SEL-AdvancedSettings=RCC_PLL3VCOMEDIUM
RCC.PLLFRACN=0
RCC.PLLSourceVirtual=RCC_PLLSOURCE_HSE
RCC.SYSCLKFreq_VALUE=480000000
RCC.SYSCLKSource=RCC_SYSCLKSOURCE_PLLCLK
RCC.Tim1Mul=1
RCC.USBFreq_Value=160000000
SH.ADCx_INP10.0=ADC1_INP10,IN10-Single-Ended
SH.ADCx_INP11.0=ADC2_INP11,IN11-Single-Ended
SH.ADCx_INP14.0=ADC1_INP14,IN14-Single-Ended
SH.ADCx_INP15.0=ADC2_INP15,IN15-Single-Ended
SH.ADCx_INP4.0=ADC2_INP4,IN4-Single-Ended
SH.S_TIM1_CH1.0=TIM1_CH1,PWM Generation1 CH1 CH1N
SH.S_TIM1_CH2.0=TIM1_CH2,PWM Generation2 CH2 CH2N
SH.S_TIM1_CH3.0=TIM1_CH3,PWM Generation3 CH3 CH3N
SH.S_TIM2_CH4.0=TIM2_CH4,PWM Generation4 CH4
SH.S_TIM3_CH1.0=TIM3_CH1,Encoder_Interface
SH.S_TIM3_CH2.0=TIM3_CH2,Encoder_Interface
SH.S_TIM3_CH3.0=TIM3_CH3,Input_Capture3_from_TI3
SPI1.BaudRatePrescaler=SPI_BAUDRATEPRESCALER_16
SPI1.CLKPhase=SPI_PHASE_2EDGE
SPI1.CLKPolarity=SPI_POLARITY_HIGH
SPI1.CalculateBaudRate=10.0 MBits/s
SPI1.DataSize=SPI_DATASIZE_8BIT
SPI1.Direction=SPI_DIRECTION_2LINES
SPI1.MasterInterDataIdleness=SPI_MASTER_INTERDATA_IDLENESS_01CYCLE
SPI1.MasterSSIdleness=SPI_MASTER_SS_IDLENESS_01CYCLE
SPI1.Mode=SPI_MODE_MASTER
SPI1.NSSPMode=SPI_NSS_PULSE_ENABLE
SPI1.VirtualNSS=VM_NSSHARD
SPI1.VirtualType=VM_MASTER
SPI2.BaudRatePrescaler=SPI_BAUDRATEPRESCALER_16
SPI2.CLKPhase=SPI_PHASE_2EDGE
SPI2.CLKPolarity=SPI_POLARITY_HIGH
SPI2.CalculateBaudRate=10.0 MBits/s
SPI2.DataSize=SPI_DATASIZE_8BIT
SPI2.Direction=SPI_DIRECTION_2LINES
SPI2.MasterInterDataIdleness=SPI_MASTER_INTERDATA_IDLENESS_01CYCLE
SPI2.MasterSSIdleness=SPI_MASTER_SS_IDLENESS_01CYCLE
SPI2.Mode=SPI_MODE_MASTER
SPI2.NSSPMode=SPI_NSS_PULSE_ENABLE
SPI2.VirtualNSS=VM_NSSHARD
SPI2.VirtualType=VM_MASTER
SPI3.BaudRatePrescaler=SPI_BAUDRATEPRESCALER_32
SPI3.CLKPhase=SPI_PHASE_1EDGE
SPI3.CalculateBaudRate=5.0 MBits/s
SPI3.DataSize=SPI_DATASIZE_8BIT
SPI3.Direction=SPI_DIRECTION_2LINES
SPI3.Mode=SPI_MODE_MASTER
SPI3.NSSPMode=SPI_NSS_PULSE_DISABLE
SPI3.VirtualType=VM_MASTER
SPI6.BaudRatePrescaler=SPI_BAUDRATEPRESCALER_32
SPI6.CLKPhase=SPI_PHASE_2EDGE
SPI6.CalculateBaudRate=3.75 MBits/s
SPI6.DataSize=SPI_DATASIZE_16BIT
SPI6.Direction=SPI_DIRECTION_2LINES
SPI6.Mode=SPI_MODE_MASTER
SPI6.NSSPMode=SPI_NSS_PULSE_DISABLE
SPI6.VirtualType=VM_MASTER
TIM1.BreakFilter=8
TIM1.BreakPolarity=TIM_BREAKPOLARITY_LOW
TIM1.BreakState=TIM_BREAK_ENABLE
TIM1.Channel-PWM\ Generation1\ CH1\ CH1N=TIM_CHANNEL_1
TIM1.Channel-PWM\ Generation2\ CH2\ CH2N=TIM_CHANNEL_2
TIM1.Channel-PWM\ Generation3\ CH3\ CH3N=TIM_CHANNEL_3
TIM1.Channel-PWM\ Generation4\ No\ Output=TIM_CHANNEL_4
TIM1.CounterMode=TIM_COUNTERMODE_CENTERALIGNED1
TIM1.DeadTime=25
TIM1.OCMode_PWM-PWM\ Generation1\ CH1\ CH1N=TIM_OCMODE_PWM2
TIM1.OCMode_PWM-PWM\ Generation2\ CH2\ CH2N=TIM_OCMODE_PWM2
TIM1.OCMode_PWM-PWM\ Generation3\ CH3\ CH3N=TIM_OCMODE_PWM2
TIM1.OCMode_PWM-PWM\ Generation4\ No\ Output=TIM_OCMODE_PWM2
TIM1.OffStateIDLEMode=TIM_OSSI_ENABLE
TIM1.OffStateRunMode=TIM_OSSR_ENABLE
TIM1.Period=6000
TIM1.Pulse-PWM\ Generation1\ CH1\ CH1N=3000
TIM1.Pulse-PWM\ Generation2\ CH2\ CH2N=3000
TIM1.Pulse-PWM\ Generation3\ CH3\ CH3N=3000
TIM1.Pulse-PWM\ Generation4\ No\ Output=1
TIM1.SourceBRKDigInput=TIM_BREAKINPUTSOURCE_ENABLE
TIM1.TIM_MasterOutputTrigger=TIM_TRGO_OC4REF
TIM1.TIM_MasterSlaveMode=TIM_MASTERSLAVEMODE_ENABLE
TIM13.Period=1000-1
TIM13.Prescaler=240-1
TIM2.AutoReloadPreload=TIM_AUTORELOAD_PRELOAD_ENABLE
TIM2.Channel-PWM\ Generation4\ CH4=TIM_CHANNEL_4
TIM2.Period=12000-1
TIM3.Channel-Input_Capture3_from_TI3=TIM_CHANNEL_3
TIM3.EncoderMode=TIM_ENCODERMODE_TI12
TIM5.AutoReloadPreload=TIM_AUTORELOAD_PRELOAD_ENABLE
TIM5.Period=24000-1
TIM6.Period=1000-1
TIM6.Prescaler=240-1
TIM7.Period=1000-1
TIM7.Prescaler=240-1
UART4.BaudRate=2500000
UART8.BaudRate=2500000
USART1.VirtualMode-Synchronous=VM_SYNC
USART2.BaudRate=921600
USART2.FIFOMode=FIFOMODE_DISABLE
USART2.VirtualMode-Asynchronous=VM_ASYNC
USART2.VirtualMode-Hardware\ Flow\ Control\ (RS485)=VM_ASYNC
VP_ADC3_TempSens_Input.Mode=IN-TempSens
VP_CRC_VS_CRC.Mode=CRC_Activate
VP_MEMORYMAP_VS_MEMORYMAP.Mode=CurAppReg
VP_TIM13_VS_ClockSourceINT.Mode=Enable_Timer
VP_TIM1_VS_ClockSourceINT.Mode=Internal
VP_TIM1_VS_no_output4.Mode=PWM Generation4 No Output
VP_TIM2_VS_ClockSourceINT.Mode=Internal
VP_TIM5_VS_ClockSourceINT.Mode=Internal
VP_TIM6_VS_ClockSourceINT.Mode=Enable_Timer
VP_TIM7_VS_ClockSourceINT.Mode=Enable_Timer
board=custom

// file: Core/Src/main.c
/* USER CODE BEGIN Header */
/**
  ******************************************************************************
  * @file           : main.c
  * @brief          : Main program body
  ******************************************************************************
  * @attention
  *
  * Copyright (c) 2025 STMicroelectronics.
  * All rights reserved.
  *
  * This software is licensed under terms that can be found in the LICENSE file
  * in the root directory of this software component.
  * If no LICENSE file comes with this software, it is provided AS-IS.
  *
  ******************************************************************************
  */
/* USER CODE END Header */
#include "main.h"

/* USER CODE BEGIN Includes */
#include "board.h"
#include "app_scheduler.h"
#include "app_status_check.h"

#ifdef USE_ECAT
#include "ecat_app.h"
#endif
/* USER CODE END Includes */

ADC_HandleTypeDef hadc1;
ADC_HandleTypeDef hadc2;
ADC_HandleTypeDef hadc3;
DMA_HandleTypeDef hdma_adc1;
DMA_HandleTypeDef hdma_adc2;
DMA_HandleTypeDef hdma_adc3;

CRC_HandleTypeDef hcrc;

FDCAN_HandleTypeDef hfdcan1;

I2C_HandleTypeDef hi2c1;

QSPI_HandleTypeDef hqspi;

SPI_HandleTypeDef hspi1;
SPI_HandleTypeDef hspi2;
SPI_HandleTypeDef hspi3;
SPI_HandleTypeDef hspi6;
DMA_HandleTypeDef hdma_spi1_rx;
DMA_HandleTypeDef hdma_spi1_tx;
DMA_HandleTypeDef hdma_spi2_rx;
DMA_HandleTypeDef hdma_spi2_tx;

TIM_HandleTypeDef htim1;
TIM_HandleTypeDef htim2;
TIM_HandleTypeDef htim3;
TIM_HandleTypeDef htim5;
TIM_HandleTypeDef htim6;
TIM_HandleTypeDef htim7;
TIM_HandleTypeDef htim13;

UART_HandleTypeDef huart4;
UART_HandleTypeDef huart8;
USART_HandleTypeDef husart1;
UART_HandleTypeDef huart2;
DMA_HandleTypeDef hdma_uart4_rx;
DMA_HandleTypeDef hdma_uart4_tx;
DMA_HandleTypeDef hdma_uart8_rx;
DMA_HandleTypeDef hdma_uart8_tx;
DMA_HandleTypeDef hdma_usart2_rx;
DMA_HandleTypeDef hdma_usart2_tx;

void SystemClock_Config(void);
void PeriphCommonClock_Config(void);
static void MX_GPIO_Init(void);
static void MX_DMA_Init(void);
static void MX_ADC1_Init(void);
static void MX_ADC2_Init(void);
static void MX_ADC3_Init(void);
static void MX_TIM1_Init(void);
static void MX_TIM2_Init(void);
static void MX_TIM3_Init(void);
static void MX_TIM5_Init(void);
static void MX_TIM6_Init(void);
static void MX_TIM7_Init(void);
static void MX_TIM13_Init(void);
static void MX_QUADSPI_Init(void);
static void MX_FDCAN1_Init(void);
static void MX_SPI1_Init(void);
static void MX_SPI2_Init(void);
static void MX_SPI3_Init(void);
static void MX_SPI6_Init(void);
static void MX_USART1_Init(void);
static void MX_USART2_UART_Init(void);
static void MX_UART4_Init(void);
static void MX_UART8_Init(void);
static void MX_I2C1_Init(void);
static void MX_CRC_Init(void);

int main(void)
{

  /* MCU Configuration--------------------------------------------------------*/

  /* Reset of all peripherals, Initializes the Flash interface and the Systick. */
  HAL_Init();

  /* Configure the system clock */
  SystemClock_Config();

  /* Configure the peripherals common clocks */
  PeriphCommonClock_Config();

  /* Initialize all configured peripherals */
  MX_GPIO_Init();
  MX_DMA_Init();
  MX_ADC1_Init();
  MX_ADC2_Init();
  MX_ADC3_Init();
  MX_TIM1_Init();
  MX_TIM2_Init();
  MX_TIM3_Init();
  MX_TIM5_Init();
  MX_TIM6_Init();
  MX_TIM7_Init();
  MX_TIM13_Init();
  MX_QUADSPI_Init();
  MX_FDCAN1_Init();
  MX_SPI1_Init();
  MX_SPI2_Init();
  MX_SPI3_Init();
  MX_SPI6_Init();
  MX_USART1_Init();
  MX_USART2_UART_Init();
  MX_UART4_Init();
  MX_UART8_Init();
  MX_I2C1_Init();
  MX_CRC_Init();
  /* USER CODE BEGIN 2 */
  // 部分应用注册回调函数
  RegisterSetAppCallback(set_app);
  RegisterCheckErrorCallback(app_get_check_error_val);
  RegisterCheckWarningCallback(app_get_check_warning_val);
  RegisterCheckStatusCallback(app_get_check_status_val);
  RegisterCheckIoInputsStatusCallback(app_get_check_di_io_val);
  RegisterSendCallback(mavlink_send_data);

  // 硬件及应用初始化
  HalInit();
  BspInit();

#ifdef USE_ECAT
  ecat_main();
#endif
  /* USER CODE END 2 */

  /* Infinite loop */
  while (1)
  {

  }
}

void SystemClock_Config(void)
{
  RCC_OscInitTypeDef RCC_OscInitStruct = {0};
  RCC_ClkInitTypeDef RCC_ClkInitStruct = {0};

  /** Supply configuration update enable
  */
  HAL_PWREx_ConfigSupply(PWR_LDO_SUPPLY);

  /** Configure the main internal regulator output voltage
  */
  __HAL_PWR_VOLTAGESCALING_CONFIG(PWR_REGULATOR_VOLTAGE_SCALE1);

  while(!__HAL_PWR_GET_FLAG(PWR_FLAG_VOSRDY)) {}

  __HAL_RCC_SYSCFG_CLK_ENABLE();
  __HAL_PWR_VOLTAGESCALING_CONFIG(PWR_REGULATOR_VOLTAGE_SCALE0);

  while(!__HAL_PWR_GET_FLAG(PWR_FLAG_VOSRDY)) {}

  /** Initializes the RCC Oscillators according to the specified parameters
  * in the RCC_OscInitTypeDef structure.
  */
  RCC_OscInitStruct.OscillatorType = RCC_OSCILLATORTYPE_HSE;
  RCC_OscInitStruct.HSEState = RCC_HSE_BYPASS;
  RCC_OscInitStruct.PLL.PLLState = RCC_PLL_ON;
  RCC_OscInitStruct.PLL.PLLSource = RCC_PLLSOURCE_HSE;
  RCC_OscInitStruct.PLL.PLLM = 1;
  RCC_OscInitStruct.PLL.PLLN = 60;
  RCC_OscInitStruct.PLL.PLLP = 2;
  RCC_OscInitStruct.PLL.PLLQ = 6;
  RCC_OscInitStruct.PLL.PLLR = 2;
  RCC_OscInitStruct.PLL.PLLRGE = RCC_PLL1VCIRANGE_3;
  RCC_OscInitStruct.PLL.PLLVCOSEL = RCC_PLL1VCOWIDE;
  RCC_OscInitStruct.PLL.PLLFRACN = 0;
  if (HAL_RCC_OscConfig(&RCC_OscInitStruct) != HAL_OK)
  {
    Error_Handler();
  }

  /** Initializes the CPU, AHB and APB buses clocks
  */
  RCC_ClkInitStruct.ClockType = RCC_CLOCKTYPE_HCLK|RCC_CLOCKTYPE_SYSCLK
                              |RCC_CLOCKTYPE_PCLK1|RCC_CLOCKTYPE_PCLK2
                              |RCC_CLOCKTYPE_D3PCLK1|RCC_CLOCKTYPE_D1PCLK1;
  RCC_ClkInitStruct.SYSCLKSource = RCC_SYSCLKSOURCE_PLLCLK;
  RCC_ClkInitStruct.SYSCLKDivider = RCC_SYSCLK_DIV1;
  RCC_ClkInitStruct.AHBCLKDivider = RCC_HCLK_DIV2;
  RCC_ClkInitStruct.APB3CLKDivider = RCC_APB3_DIV2;
  RCC_ClkInitStruct.APB1CLKDivider = RCC_APB1_DIV2;
  RCC_ClkInitStruct.APB2CLKDivider = RCC_APB2_DIV2;
  RCC_ClkInitStruct.APB4CLKDivider = RCC_APB4_DIV2;

  if (HAL_RCC_ClockConfig(&RCC_ClkInitStruct, FLASH_LATENCY_4) != HAL_OK)
  {
    Error_Handler();
  }
}

void PeriphCommonClock_Config(void)
{
  RCC_PeriphCLKInitTypeDef PeriphClkInitStruct = {0};

  /** Initializes the peripherals clock
  */
  PeriphClkInitStruct.PeriphClockSelection = RCC_PERIPHCLK_ADC|RCC_PERIPHCLK_FDCAN;
  PeriphClkInitStruct.PLL2.PLL2M = 1;
  PeriphClkInitStruct.PLL2.PLL2N = 10;
  PeriphClkInitStruct.PLL2.PLL2P = 2;
  PeriphClkInitStruct.PLL2.PLL2Q = 2;
  PeriphClkInitStruct.PLL2.PLL2R = 2;
  PeriphClkInitStruct.PLL2.PLL2RGE = RCC_PLL2VCIRANGE_3;
  PeriphClkInitStruct.PLL2.PLL2VCOSEL = RCC_PLL2VCOMEDIUM;
  PeriphClkInitStruct.PLL2.PLL2FRACN = 0;
  PeriphClkInitStruct.FdcanClockSelection = RCC_FDCANCLKSOURCE_PLL2;
  PeriphClkInitStruct.AdcClockSelection = RCC_ADCCLKSOURCE_PLL2;
  if (HAL_RCCEx_PeriphCLKConfig(&PeriphClkInitStruct) != HAL_OK)
  {
    Error_Handler();
  }
}

static void MX_ADC1_Init(void)
{

  ADC_MultiModeTypeDef multimode = {0};
  ADC_ChannelConfTypeDef sConfig = {0};
  ADC_InjectionConfTypeDef sConfigInjected = {0};

  /** Common config
  */
  hadc1.Instance = ADC1;
  hadc1.Init.ScanConvMode = ADC_SCAN_ENABLE;
  hadc1.Init.EOCSelection = ADC_EOC_SINGLE_CONV;
  hadc1.Init.LowPowerAutoWait = DISABLE;
  hadc1.Init.ContinuousConvMode = ENABLE;
  hadc1.Init.NbrOfConversion = 2;
  hadc1.Init.DiscontinuousConvMode = DISABLE;
  hadc1.Init.NbrOfDiscConversion = 2;
  hadc1.Init.ExternalTrigConv = ADC_SOFTWARE_START;
  hadc1.Init.ExternalTrigConvEdge = ADC_EXTERNALTRIGCONVEDGE_NONE;
  hadc1.Init.ConversionDataManagement = ADC_CONVERSIONDATA_DMA_CIRCULAR;
  hadc1.Init.Overrun = ADC_OVR_DATA_PRESERVED;
  hadc1.Init.LeftBitShift = ADC_LEFTBITSHIFT_NONE;
  hadc1.Init.OversamplingMode = DISABLE;
  hadc1.Init.Oversampling.Ratio = 1;
  if (HAL_ADC_Init(&hadc1) != HAL_OK)
  {
    Error_Handler();
  }
  hadc1.Init.ClockPrescaler = ADC_CLOCK_ASYNC_DIV1;
  hadc1.Init.Resolution = ADC_RESOLUTION_16B;
  if (HAL_ADC_Init(&hadc1) != HAL_OK)
  {
    Error_Handler();
  }

  /** Configure the ADC multi-mode
  */
  multimode.Mode = ADC_MODE_INDEPENDENT;
  if (HAL_ADCEx_MultiModeConfigChannel(&hadc1, &multimode) != HAL_OK)
  {
    Error_Handler();
  }

  /** Disable Injected Queue
  */
  HAL_ADCEx_DisableInjectedQueue(&hadc1);

  /** Configure Regular Channel
  */
  sConfig.Channel = ADC_CHANNEL_14;
  sConfig.Rank = ADC_REGULAR_RANK_1;
  sConfig.SamplingTime = ADC_SAMPLETIME_2CYCLES_5;
  sConfig.SingleDiff = ADC_SINGLE_ENDED;
  sConfig.OffsetNumber = ADC_OFFSET_NONE;
  sConfig.Offset = 0;
  sConfig.OffsetSignedSaturation = DISABLE;
  if (HAL_ADC_ConfigChannel(&hadc1, &sConfig) != HAL_OK)
  {
    Error_Handler();
  }

  /** Configure Regular Channel
  */
  sConfig.Channel = ADC_CHANNEL_16;
  sConfig.Rank = ADC_REGULAR_RANK_2;
  if (HAL_ADC_ConfigChannel(&hadc1, &sConfig) != HAL_OK)
  {
    Error_Handler();
  }

  /** Configure Injected Channel
  */
  sConfigInjected.InjectedChannel = ADC_CHANNEL_10;
  sConfigInjected.InjectedRank = ADC_INJECTED_RANK_1;
  sConfigInjected.InjectedSamplingTime = ADC_SAMPLETIME_2CYCLES_5;
  sConfigInjected.InjectedSingleDiff = ADC_SINGLE_ENDED;
  sConfigInjected.InjectedOffsetNumber = ADC_OFFSET_NONE;
  sConfigInjected.InjectedOffset = 0;
  sConfigInjected.InjectedOffsetSignedSaturation = DISABLE;
  sConfigInjected.InjectedNbrOfConversion = 1;
  sConfigInjected.InjectedDiscontinuousConvMode = DISABLE;
  sConfigInjected.AutoInjectedConv = DISABLE;
  sConfigInjected.QueueInjectedContext = DISABLE;
  sConfigInjected.ExternalTrigInjecConv = ADC_EXTERNALTRIGINJEC_T1_TRGO;
  sConfigInjected.ExternalTrigInjecConvEdge = ADC_EXTERNALTRIGINJECCONV_EDGE_RISING;
  sConfigInjected.InjecOversamplingMode = DISABLE;
  if (HAL_ADCEx_InjectedConfigChannel(&hadc1, &sConfigInjected) != HAL_OK)
  {
    Error_Handler();
  }

}

static void MX_ADC2_Init(void)
{

  ADC_ChannelConfTypeDef sConfig = {0};
  ADC_InjectionConfTypeDef sConfigInjected = {0};

  /** Common config
  */
  hadc2.Instance = ADC2;
  hadc2.Init.ScanConvMode = ADC_SCAN_ENABLE;
  hadc2.Init.EOCSelection = ADC_EOC_SINGLE_CONV;
  hadc2.Init.LowPowerAutoWait = DISABLE;
  hadc2.Init.ContinuousConvMode = ENABLE;
  hadc2.Init.NbrOfConversion = 2;
  hadc2.Init.DiscontinuousConvMode = DISABLE;
  hadc2.Init.NbrOfDiscConversion = 2;
  hadc2.Init.ExternalTrigConv = ADC_SOFTWARE_START;
  hadc2.Init.ExternalTrigConvEdge = ADC_EXTERNALTRIGCONVEDGE_NONE;
  hadc2.Init.ConversionDataManagement = ADC_CONVERSIONDATA_DMA_CIRCULAR;
  hadc2.Init.Overrun = ADC_OVR_DATA_PRESERVED;
  hadc2.Init.LeftBitShift = ADC_LEFTBITSHIFT_NONE;
  hadc2.Init.OversamplingMode = DISABLE;
  hadc2.Init.Oversampling.Ratio = 1;
  if (HAL_ADC_Init(&hadc2) != HAL_OK)
  {
    Error_Handler();
  }
  hadc2.Init.ClockPrescaler = ADC_CLOCK_ASYNC_DIV1;
  hadc2.Init.Resolution = ADC_RESOLUTION_16B;
  if (HAL_ADC_Init(&hadc2) != HAL_OK)
  {
    Error_Handler();
  }

  /** Disable Injected Queue
  */
  HAL_ADCEx_DisableInjectedQueue(&hadc2);

  /** Configure Regular Channel
  */
  sConfig.Channel = ADC_CHANNEL_15;
  sConfig.Rank = ADC_REGULAR_RANK_1;
  sConfig.SamplingTime = ADC_SAMPLETIME_387CYCLES_5;
  sConfig.SingleDiff = ADC_SINGLE_ENDED;
  sConfig.OffsetNumber = ADC_OFFSET_NONE;
  sConfig.Offset = 0;
  sConfig.OffsetSignedSaturation = DISABLE;
  if (HAL_ADC_ConfigChannel(&hadc2, &sConfig) != HAL_OK)
  {
    Error_Handler();
  }

  /** Configure Regular Channel
  */
  sConfig.Channel = ADC_CHANNEL_4;
  sConfig.Rank = ADC_REGULAR_RANK_2;
  sConfig.SamplingTime = ADC_SAMPLETIME_2CYCLES_5;
  if (HAL_ADC_ConfigChannel(&hadc2, &sConfig) != HAL_OK)
  {
    Error_Handler();
  }

  /** Configure Injected Channel
  */
  sConfigInjected.InjectedChannel = ADC_CHANNEL_11;
  sConfigInjected.InjectedRank = ADC_INJECTED_RANK_1;
  sConfigInjected.InjectedSamplingTime = ADC_SAMPLETIME_2CYCLES_5;
  sConfigInjected.InjectedSingleDiff = ADC_SINGLE_ENDED;
  sConfigInjected.InjectedOffsetNumber = ADC_OFFSET_NONE;
  sConfigInjected.InjectedOffset = 0;
  sConfigInjected.InjectedOffsetSignedSaturation = DISABLE;
  sConfigInjected.InjectedNbrOfConversion = 1;
  sConfigInjected.InjectedDiscontinuousConvMode = DISABLE;
  sConfigInjected.AutoInjectedConv = DISABLE;
  sConfigInjected.QueueInjectedContext = DISABLE;
  sConfigInjected.ExternalTrigInjecConv = ADC_EXTERNALTRIGINJEC_T1_TRGO;
  sConfigInjected.ExternalTrigInjecConvEdge = ADC_EXTERNALTRIGINJECCONV_EDGE_RISING;
  sConfigInjected.InjecOversamplingMode = DISABLE;
  if (HAL_ADCEx_InjectedConfigChannel(&hadc2, &sConfigInjected) != HAL_OK)
  {
    Error_Handler();
  }

}

static void MX_ADC3_Init(void)
{

  ADC_ChannelConfTypeDef sConfig = {0};
  ADC_InjectionConfTypeDef sConfigInjected = {0};

  /** Common config
  */
  hadc3.Instance = ADC3;
  hadc3.Init.ClockPrescaler = ADC_CLOCK_ASYNC_DIV1;
  hadc3.Init.ScanConvMode = ADC_SCAN_ENABLE;
  hadc3.Init.EOCSelection = ADC_EOC_SINGLE_CONV;
  hadc3.Init.LowPowerAutoWait = DISABLE;
  hadc3.Init.ContinuousConvMode = ENABLE;
  hadc3.Init.NbrOfConversion = 2;
  hadc3.Init.DiscontinuousConvMode = DISABLE;
  hadc3.Init.NbrOfDiscConversion = 2;
  hadc3.Init.ExternalTrigConv = ADC_SOFTWARE_START;
  hadc3.Init.ExternalTrigConvEdge = ADC_EXTERNALTRIGCONVEDGE_NONE;
  hadc3.Init.ConversionDataManagement = ADC_CONVERSIONDATA_DMA_CIRCULAR;
  hadc3.Init.Overrun = ADC_OVR_DATA_PRESERVED;
  hadc3.Init.LeftBitShift = ADC_LEFTBITSHIFT_NONE;
  hadc3.Init.OversamplingMode = DISABLE;
  hadc3.Init.Oversampling.Ratio = 1;
  if (HAL_ADC_Init(&hadc3) != HAL_OK)
  {
    Error_Handler();
  }
  hadc3.Init.Resolution = ADC_RESOLUTION_16B;
  if (HAL_ADC_Init(&hadc3) != HAL_OK)
  {
    Error_Handler();
  }

  /** Disable Injected Queue
  */
  HAL_ADCEx_DisableInjectedQueue(&hadc3);

  /** Configure Regular Channel
  */
  sConfig.Channel = ADC_CHANNEL_TEMPSENSOR;
  sConfig.Rank = ADC_REGULAR_RANK_1;
  sConfig.SamplingTime = ADC_SAMPLETIME_810CYCLES_5;
  sConfig.SingleDiff = ADC_SINGLE_ENDED;
  sConfig.OffsetNumber = ADC_OFFSET_NONE;
  sConfig.Offset = 0;
  sConfig.OffsetSignedSaturation = DISABLE;
  if (HAL_ADC_ConfigChannel(&hadc3, &sConfig) != HAL_OK)
  {
    Error_Handler();
  }

  /** Configure Regular Channel
  */
  sConfig.Channel = ADC_CHANNEL_1;
  sConfig.Rank = ADC_REGULAR_RANK_2;
  sConfig.SamplingTime = ADC_SAMPLETIME_387CYCLES_5;
  if (HAL_ADC_ConfigChannel(&hadc3, &sConfig) != HAL_OK)
  {
    Error_Handler();
  }

  /** Configure Injected Channel
  */
  sConfigInjected.InjectedChannel = ADC_CHANNEL_0;
  sConfigInjected.InjectedRank = ADC_INJECTED_RANK_1;
  sConfigInjected.InjectedSamplingTime = ADC_SAMPLETIME_2CYCLES_5;
  sConfigInjected.InjectedSingleDiff = ADC_SINGLE_ENDED;
  sConfigInjected.InjectedOffsetNumber = ADC_OFFSET_NONE;
  sConfigInjected.InjectedOffset = 0;
  sConfigInjected.InjectedOffsetSignedSaturation = DISABLE;
  sConfigInjected.InjectedNbrOfConversion = 1;
  sConfigInjected.InjectedDiscontinuousConvMode = DISABLE;
  sConfigInjected.AutoInjectedConv = DISABLE;
  sConfigInjected.QueueInjectedContext = DISABLE;
  sConfigInjected.ExternalTrigInjecConv = ADC_EXTERNALTRIGINJEC_T1_TRGO;
  sConfigInjected.ExternalTrigInjecConvEdge = ADC_EXTERNALTRIGINJECCONV_EDGE_RISING;
  sConfigInjected.InjecOversamplingMode = DISABLE;
  if (HAL_ADCEx_InjectedConfigChannel(&hadc3, &sConfigInjected) != HAL_OK)
  {
    Error_Handler();
  }

}

static void MX_CRC_Init(void)
{

  hcrc.Instance = CRC;
  hcrc.Init.DefaultPolynomialUse = DEFAULT_POLYNOMIAL_ENABLE;
  hcrc.Init.DefaultInitValueUse = DEFAULT_INIT_VALUE_ENABLE;
  hcrc.Init.InputDataInversionMode = CRC_INPUTDATA_INVERSION_NONE;
  hcrc.Init.OutputDataInversionMode = CRC_OUTPUTDATA_INVERSION_DISABLE;
  hcrc.InputDataFormat = CRC_INPUTDATA_FORMAT_WORDS;
  if (HAL_CRC_Init(&hcrc) != HAL_OK)
  {
    Error_Handler();
  }

}

static void MX_FDCAN1_Init(void)
{

  hfdcan1.Instance = FDCAN1;
  hfdcan1.Init.FrameFormat = FDCAN_FRAME_FD_BRS;
  hfdcan1.Init.Mode = FDCAN_MODE_NORMAL;
  hfdcan1.Init.AutoRetransmission = ENABLE;
  hfdcan1.Init.TransmitPause = ENABLE;
  hfdcan1.Init.ProtocolException = ENABLE;
  hfdcan1.Init.NominalPrescaler = 8;
  hfdcan1.Init.NominalSyncJumpWidth = 2;
  hfdcan1.Init.NominalTimeSeg1 = 7;
  hfdcan1.Init.NominalTimeSeg2 = 2;
  hfdcan1.Init.DataPrescaler = 8;
  hfdcan1.Init.DataSyncJumpWidth = 1;
  hfdcan1.Init.DataTimeSeg1 = 7;
  hfdcan1.Init.DataTimeSeg2 = 2;
  hfdcan1.Init.MessageRAMOffset = 0;
  hfdcan1.Init.StdFiltersNbr = 128;
  hfdcan1.Init.ExtFiltersNbr = 64;
  hfdcan1.Init.RxFifo0ElmtsNbr = 32;
  hfdcan1.Init.RxFifo0ElmtSize = FDCAN_DATA_BYTES_64;
  hfdcan1.Init.RxFifo1ElmtsNbr = 32;
  hfdcan1.Init.RxFifo1ElmtSize = FDCAN_DATA_BYTES_64;
  hfdcan1.Init.RxBuffersNbr = 8;
  hfdcan1.Init.RxBufferSize = FDCAN_DATA_BYTES_64;
  hfdcan1.Init.TxEventsNbr = 0;
  hfdcan1.Init.TxBuffersNbr = 0;
  hfdcan1.Init.TxFifoQueueElmtsNbr = 32;
  hfdcan1.Init.TxFifoQueueMode = FDCAN_TX_FIFO_OPERATION;
  hfdcan1.Init.TxElmtSize = FDCAN_DATA_BYTES_64;
  if (HAL_FDCAN_Init(&hfdcan1) != HAL_OK)
  {
    Error_Handler();
  }

}

static void MX_I2C1_Init(void)
{

  hi2c1.Instance = I2C1;
  hi2c1.Init.Timing = 0x40805E8A;
  hi2c1.Init.OwnAddress1 = 0;
  hi2c1.Init.AddressingMode = I2C_ADDRESSINGMODE_7BIT;
  hi2c1.Init.DualAddressMode = I2C_DUALADDRESS_DISABLE;
  hi2c1.Init.OwnAddress2 = 0;
  hi2c1.Init.OwnAddress2Masks = I2C_OA2_NOMASK;
  hi2c1.Init.GeneralCallMode = I2C_GENERALCALL_DISABLE;
  hi2c1.Init.NoStretchMode = I2C_NOSTRETCH_DISABLE;
  if (HAL_I2C_Init(&hi2c1) != HAL_OK)
  {
    Error_Handler();
  }

  /** Configure Analogue filter
  */
  if (HAL_I2CEx_ConfigAnalogFilter(&hi2c1, I2C_ANALOGFILTER_ENABLE) != HAL_OK)
  {
    Error_Handler();
  }

  /** Configure Digital filter
  */
  if (HAL_I2CEx_ConfigDigitalFilter(&hi2c1, 0) != HAL_OK)
  {
    Error_Handler();
  }

}

static void MX_QUADSPI_Init(void)
{

  /* QUADSPI parameter configuration*/
  hqspi.Instance = QUADSPI;
  hqspi.Init.ClockPrescaler = 8-1;
  hqspi.Init.FifoThreshold = 4;
  hqspi.Init.SampleShifting = QSPI_SAMPLE_SHIFTING_HALFCYCLE;
  hqspi.Init.FlashSize = 15;
  hqspi.Init.ChipSelectHighTime = QSPI_CS_HIGH_TIME_1_CYCLE;
  hqspi.Init.ClockMode = QSPI_CLOCK_MODE_3;
  hqspi.Init.FlashID = QSPI_FLASH_ID_1;
  hqspi.Init.DualFlash = QSPI_DUALFLASH_DISABLE;
  if (HAL_QSPI_Init(&hqspi) != HAL_OK)
  {
    Error_Handler();
  }

}

static void MX_SPI1_Init(void)
{

  /* SPI1 parameter configuration*/
  hspi1.Instance = SPI1;
  hspi1.Init.Mode = SPI_MODE_MASTER;
  hspi1.Init.Direction = SPI_DIRECTION_2LINES;
  hspi1.Init.DataSize = SPI_DATASIZE_8BIT;
  hspi1.Init.CLKPolarity = SPI_POLARITY_HIGH;
  hspi1.Init.CLKPhase = SPI_PHASE_2EDGE;
  hspi1.Init.NSS = SPI_NSS_HARD_OUTPUT;
  hspi1.Init.BaudRatePrescaler = SPI_BAUDRATEPRESCALER_16;
  hspi1.Init.FirstBit = SPI_FIRSTBIT_MSB;
  hspi1.Init.TIMode = SPI_TIMODE_DISABLE;
  hspi1.Init.CRCCalculation = SPI_CRCCALCULATION_DISABLE;
  hspi1.Init.CRCPolynomial = 0x0;
  hspi1.Init.NSSPMode = SPI_NSS_PULSE_ENABLE;
  hspi1.Init.NSSPolarity = SPI_NSS_POLARITY_LOW;
  hspi1.Init.FifoThreshold = SPI_FIFO_THRESHOLD_01DATA;
  hspi1.Init.TxCRCInitializationPattern = SPI_CRC_INITIALIZATION_ALL_ZERO_PATTERN;
  hspi1.Init.RxCRCInitializationPattern = SPI_CRC_INITIALIZATION_ALL_ZERO_PATTERN;
  hspi1.Init.MasterSSIdleness = SPI_MASTER_SS_IDLENESS_01CYCLE;
  hspi1.Init.MasterInterDataIdleness = SPI_MASTER_INTERDATA_IDLENESS_01CYCLE;
  hspi1.Init.MasterReceiverAutoSusp = SPI_MASTER_RX_AUTOSUSP_DISABLE;
  hspi1.Init.MasterKeepIOState = SPI_MASTER_KEEP_IO_STATE_DISABLE;
  hspi1.Init.IOSwap = SPI_IO_SWAP_DISABLE;
  if (HAL_SPI_Init(&hspi1) != HAL_OK)
  {
    Error_Handler();
  }

}

static void MX_SPI2_Init(void)
{

  /* SPI2 parameter configuration*/
  hspi2.Instance = SPI2;
  hspi2.Init.Mode = SPI_MODE_MASTER;
  hspi2.Init.Direction = SPI_DIRECTION_2LINES;
  hspi2.Init.DataSize = SPI_DATASIZE_8BIT;
  hspi2.Init.CLKPolarity = SPI_POLARITY_HIGH;
  hspi2.Init.CLKPhase = SPI_PHASE_2EDGE;
  hspi2.Init.NSS = SPI_NSS_HARD_OUTPUT;
  hspi2.Init.BaudRatePrescaler = SPI_BAUDRATEPRESCALER_16;
  hspi2.Init.FirstBit = SPI_FIRSTBIT_MSB;
  hspi2.Init.TIMode = SPI_TIMODE_DISABLE;
  hspi2.Init.CRCCalculation = SPI_CRCCALCULATION_DISABLE;
  hspi2.Init.CRCPolynomial = 0x0;
  hspi2.Init.NSSPMode = SPI_NSS_PULSE_ENABLE;
  hspi2.Init.NSSPolarity = SPI_NSS_POLARITY_LOW;
  hspi2.Init.FifoThreshold = SPI_FIFO_THRESHOLD_01DATA;
  hspi2.Init.TxCRCInitializationPattern = SPI_CRC_INITIALIZATION_ALL_ZERO_PATTERN;
  hspi2.Init.RxCRCInitializationPattern = SPI_CRC_INITIALIZATION_ALL_ZERO_PATTERN;
  hspi2.Init.MasterSSIdleness = SPI_MASTER_SS_IDLENESS_01CYCLE;
  hspi2.Init.MasterInterDataIdleness = SPI_MASTER_INTERDATA_IDLENESS_01CYCLE;
  hspi2.Init.MasterReceiverAutoSusp = SPI_MASTER_RX_AUTOSUSP_DISABLE;
  hspi2.Init.MasterKeepIOState = SPI_MASTER_KEEP_IO_STATE_DISABLE;
  hspi2.Init.IOSwap = SPI_IO_SWAP_DISABLE;
  if (HAL_SPI_Init(&hspi2) != HAL_OK)
  {
    Error_Handler();
  }

}

static void MX_SPI3_Init(void)
{

  /* SPI3 parameter configuration*/
  hspi3.Instance = SPI3;
  hspi3.Init.Mode = SPI_MODE_MASTER;
  hspi3.Init.Direction = SPI_DIRECTION_2LINES;
  hspi3.Init.DataSize = SPI_DATASIZE_8BIT;
  hspi3.Init.CLKPolarity = SPI_POLARITY_LOW;
  hspi3.Init.CLKPhase = SPI_PHASE_1EDGE;
  hspi3.Init.NSS = SPI_NSS_SOFT;
  hspi3.Init.BaudRatePrescaler = SPI_BAUDRATEPRESCALER_32;
  hspi3.Init.FirstBit = SPI_FIRSTBIT_MSB;
  hspi3.Init.TIMode = SPI_TIMODE_DISABLE;
  hspi3.Init.CRCCalculation = SPI_CRCCALCULATION_DISABLE;
  hspi3.Init.CRCPolynomial = 0x0;
  hspi3.Init.NSSPMode = SPI_NSS_PULSE_DISABLE;
  hspi3.Init.NSSPolarity = SPI_NSS_POLARITY_LOW;
  hspi3.Init.FifoThreshold = SPI_FIFO_THRESHOLD_01DATA;
  hspi3.Init.TxCRCInitializationPattern = SPI_CRC_INITIALIZATION_ALL_ZERO_PATTERN;
  hspi3.Init.RxCRCInitializationPattern = SPI_CRC_INITIALIZATION_ALL_ZERO_PATTERN;
  hspi3.Init.MasterSSIdleness = SPI_MASTER_SS_IDLENESS_00CYCLE;
  hspi3.Init.MasterInterDataIdleness = SPI_MASTER_INTERDATA_IDLENESS_00CYCLE;
  hspi3.Init.MasterReceiverAutoSusp = SPI_MASTER_RX_AUTOSUSP_DISABLE;
  hspi3.Init.MasterKeepIOState = SPI_MASTER_KEEP_IO_STATE_DISABLE;
  hspi3.Init.IOSwap = SPI_IO_SWAP_DISABLE;
  if (HAL_SPI_Init(&hspi3) != HAL_OK)
  {
    Error_Handler();
  }

}

static void MX_SPI6_Init(void)
{

  /* SPI6 parameter configuration*/
  hspi6.Instance = SPI6;
  hspi6.Init.Mode = SPI_MODE_MASTER;
  hspi6.Init.Direction = SPI_DIRECTION_2LINES;
  hspi6.Init.DataSize = SPI_DATASIZE_16BIT;
  hspi6.Init.CLKPolarity = SPI_POLARITY_LOW;
  hspi6.Init.CLKPhase = SPI_PHASE_2EDGE;
  hspi6.Init.NSS = SPI_NSS_SOFT;
  hspi6.Init.BaudRatePrescaler = SPI_BAUDRATEPRESCALER_32;
  hspi6.Init.FirstBit = SPI_FIRSTBIT_MSB;
  hspi6.Init.TIMode = SPI_TIMODE_DISABLE;
  hspi6.Init.CRCCalculation = SPI_CRCCALCULATION_DISABLE;
  hspi6.Init.CRCPolynomial = 0x0;
  hspi6.Init.NSSPMode = SPI_NSS_PULSE_DISABLE;
  hspi6.Init.NSSPolarity = SPI_NSS_POLARITY_LOW;
  hspi6.Init.FifoThreshold = SPI_FIFO_THRESHOLD_01DATA;
  hspi6.Init.TxCRCInitializationPattern = SPI_CRC_INITIALIZATION_ALL_ZERO_PATTERN;
  hspi6.Init.RxCRCInitializationPattern = SPI_CRC_INITIALIZATION_ALL_ZERO_PATTERN;
  hspi6.Init.MasterSSIdleness = SPI_MASTER_SS_IDLENESS_00CYCLE;
  hspi6.Init.MasterInterDataIdleness = SPI_MASTER_INTERDATA_IDLENESS_00CYCLE;
  hspi6.Init.MasterReceiverAutoSusp = SPI_MASTER_RX_AUTOSUSP_DISABLE;
  hspi6.Init.MasterKeepIOState = SPI_MASTER_KEEP_IO_STATE_DISABLE;
  hspi6.Init.IOSwap = SPI_IO_SWAP_DISABLE;
  if (HAL_SPI_Init(&hspi6) != HAL_OK)
  {
    Error_Handler();
  }

}

static void MX_TIM1_Init(void)
{

  TIM_ClockConfigTypeDef sClockSourceConfig = {0};
  TIM_MasterConfigTypeDef sMasterConfig = {0};
  TIMEx_BreakInputConfigTypeDef sBreakInputConfig = {0};
  TIM_OC_InitTypeDef sConfigOC = {0};
  TIM_BreakDeadTimeConfigTypeDef sBreakDeadTimeConfig = {0};

  htim1.Instance = TIM1;
  htim1.Init.Prescaler = 0;
  htim1.Init.CounterMode = TIM_COUNTERMODE_CENTERALIGNED1;
  htim1.Init.Period = 6000;
  htim1.Init.ClockDivision = TIM_CLOCKDIVISION_DIV1;
  htim1.Init.RepetitionCounter = 0;
  htim1.Init.AutoReloadPreload = TIM_AUTORELOAD_PRELOAD_DISABLE;
  if (HAL_TIM_Base_Init(&htim1) != HAL_OK)
  {
    Error_Handler();
  }
  sClockSourceConfig.ClockSource = TIM_CLOCKSOURCE_INTERNAL;
  if (HAL_TIM_ConfigClockSource(&htim1, &sClockSourceConfig) != HAL_OK)
  {
    Error_Handler();
  }
  if (HAL_TIM_PWM_Init(&htim1) != HAL_OK)
  {
    Error_Handler();
  }
  sMasterConfig.MasterOutputTrigger = TIM_TRGO_OC4REF;
  sMasterConfig.MasterOutputTrigger2 = TIM_TRGO2_RESET;
  sMasterConfig.MasterSlaveMode = TIM_MASTERSLAVEMODE_ENABLE;
  if (HAL_TIMEx_MasterConfigSynchronization(&htim1, &sMasterConfig) != HAL_OK)
  {
    Error_Handler();
  }
  sBreakInputConfig.Source = TIM_BREAKINPUTSOURCE_BKIN;
  sBreakInputConfig.Enable = TIM_BREAKINPUTSOURCE_ENABLE;
  sBreakInputConfig.Polarity = TIM_BREAKINPUTSOURCE_POLARITY_HIGH;
  if (HAL_TIMEx_ConfigBreakInput(&htim1, TIM_BREAKINPUT_BRK, &sBreakInputConfig) != HAL_OK)
  {
    Error_Handler();
  }
  sConfigOC.OCMode = TIM_OCMODE_PWM2;
  sConfigOC.Pulse = 3000;
  sConfigOC.OCPolarity = TIM_OCPOLARITY_HIGH;
  sConfigOC.OCNPolarity = TIM_OCNPOLARITY_HIGH;
  sConfigOC.OCFastMode = TIM_OCFAST_DISABLE;
  sConfigOC.OCIdleState = TIM_OCIDLESTATE_RESET;
  sConfigOC.OCNIdleState = TIM_OCNIDLESTATE_RESET;
  if (HAL_TIM_PWM_ConfigChannel(&htim1, &sConfigOC, TIM_CHANNEL_1) != HAL_OK)
  {
    Error_Handler();
  }
  if (HAL_TIM_PWM_ConfigChannel(&htim1, &sConfigOC, TIM_CHANNEL_2) != HAL_OK)
  {
    Error_Handler();
  }
  if (HAL_TIM_PWM_ConfigChannel(&htim1, &sConfigOC, TIM_CHANNEL_3) != HAL_OK)
  {
    Error_Handler();
  }
  sConfigOC.Pulse = 1;
  if (HAL_TIM_PWM_ConfigChannel(&htim1, &sConfigOC, TIM_CHANNEL_4) != HAL_OK)
  {
    Error_Handler();
  }
  sBreakDeadTimeConfig.OffStateRunMode = TIM_OSSR_ENABLE;
  sBreakDeadTimeConfig.OffStateIDLEMode = TIM_OSSI_ENABLE;
  sBreakDeadTimeConfig.LockLevel = TIM_LOCKLEVEL_OFF;
  sBreakDeadTimeConfig.DeadTime = 25;
  sBreakDeadTimeConfig.BreakState = TIM_BREAK_ENABLE;
  sBreakDeadTimeConfig.BreakPolarity = TIM_BREAKPOLARITY_LOW;
  sBreakDeadTimeConfig.BreakFilter = 8;
  sBreakDeadTimeConfig.Break2State = TIM_BREAK2_DISABLE;
  sBreakDeadTimeConfig.Break2Polarity = TIM_BREAK2POLARITY_HIGH;
  sBreakDeadTimeConfig.Break2Filter = 0;
  sBreakDeadTimeConfig.AutomaticOutput = TIM_AUTOMATICOUTPUT_DISABLE;
  if (HAL_TIMEx_ConfigBreakDeadTime(&htim1, &sBreakDeadTimeConfig) != HAL_OK)
  {
    Error_Handler();
  }
  HAL_TIM_MspPostInit(&htim1);

}

static void MX_TIM2_Init(void)
{

  TIM_ClockConfigTypeDef sClockSourceConfig = {0};
  TIM_MasterConfigTypeDef sMasterConfig = {0};
  TIM_OC_InitTypeDef sConfigOC = {0};

  htim2.Instance = TIM2;
  htim2.Init.Prescaler = 0;
  htim2.Init.CounterMode = TIM_COUNTERMODE_UP;
  htim2.Init.Period = 12000-1;
  htim2.Init.ClockDivision = TIM_CLOCKDIVISION_DIV1;
  htim2.Init.AutoReloadPreload = TIM_AUTORELOAD_PRELOAD_ENABLE;
  if (HAL_TIM_Base_Init(&htim2) != HAL_OK)
  {
    Error_Handler();
  }
  sClockSourceConfig.ClockSource = TIM_CLOCKSOURCE_INTERNAL;
  if (HAL_TIM_ConfigClockSource(&htim2, &sClockSourceConfig) != HAL_OK)
  {
    Error_Handler();
  }
  if (HAL_TIM_PWM_Init(&htim2) != HAL_OK)
  {
    Error_Handler();
  }
  sMasterConfig.MasterOutputTrigger = TIM_TRGO_RESET;
  sMasterConfig.MasterSlaveMode = TIM_MASTERSLAVEMODE_DISABLE;
  if (HAL_TIMEx_MasterConfigSynchronization(&htim2, &sMasterConfig) != HAL_OK)
  {
    Error_Handler();
  }
  sConfigOC.OCMode = TIM_OCMODE_PWM1;
  sConfigOC.Pulse = 0;
  sConfigOC.OCPolarity = TIM_OCPOLARITY_HIGH;
  sConfigOC.OCFastMode = TIM_OCFAST_DISABLE;
  if (HAL_TIM_PWM_ConfigChannel(&htim2, &sConfigOC, TIM_CHANNEL_4) != HAL_OK)
  {
    Error_Handler();
  }
  HAL_TIM_MspPostInit(&htim2);

}

static void MX_TIM3_Init(void)
{

  TIM_Encoder_InitTypeDef sConfig = {0};
  TIM_MasterConfigTypeDef sMasterConfig = {0};
  TIM_IC_InitTypeDef sConfigIC = {0};

  htim3.Instance = TIM3;
  htim3.Init.Prescaler = 0;
  htim3.Init.CounterMode = TIM_COUNTERMODE_UP;
  htim3.Init.Period = 65535;
  htim3.Init.ClockDivision = TIM_CLOCKDIVISION_DIV1;
  htim3.Init.AutoReloadPreload = TIM_AUTORELOAD_PRELOAD_DISABLE;
  if (HAL_TIM_IC_Init(&htim3) != HAL_OK)
  {
    Error_Handler();
  }
  sConfig.EncoderMode = TIM_ENCODERMODE_TI12;
  sConfig.IC1Polarity = TIM_ICPOLARITY_RISING;
  sConfig.IC1Selection = TIM_ICSELECTION_DIRECTTI;
  sConfig.IC1Prescaler = TIM_ICPSC_DIV1;
  sConfig.IC1Filter = 0;
  sConfig.IC2Polarity = TIM_ICPOLARITY_RISING;
  sConfig.IC2Selection = TIM_ICSELECTION_DIRECTTI;
  sConfig.IC2Prescaler = TIM_ICPSC_DIV1;
  sConfig.IC2Filter = 0;
  if (HAL_TIM_Encoder_Init(&htim3, &sConfig) != HAL_OK)
  {
    Error_Handler();
  }
  sMasterConfig.MasterOutputTrigger = TIM_TRGO_RESET;
  sMasterConfig.MasterSlaveMode = TIM_MASTERSLAVEMODE_DISABLE;
  if (HAL_TIMEx_MasterConfigSynchronization(&htim3, &sMasterConfig) != HAL_OK)
  {
    Error_Handler();
  }
  sConfigIC.ICPolarity = TIM_INPUTCHANNELPOLARITY_RISING;
  sConfigIC.ICSelection = TIM_ICSELECTION_DIRECTTI;
  sConfigIC.ICPrescaler = TIM_ICPSC_DIV1;
  sConfigIC.ICFilter = 0;
  if (HAL_TIM_IC_ConfigChannel(&htim3, &sConfigIC, TIM_CHANNEL_3) != HAL_OK)
  {
    Error_Handler();
  }

}

static void MX_TIM5_Init(void)
{

  TIM_ClockConfigTypeDef sClockSourceConfig = {0};
  TIM_MasterConfigTypeDef sMasterConfig = {0};

  htim5.Instance = TIM5;
  htim5.Init.Prescaler = 0;
  htim5.Init.CounterMode = TIM_COUNTERMODE_UP;
  htim5.Init.Period = 24000-1;
  htim5.Init.ClockDivision = TIM_CLOCKDIVISION_DIV1;
  htim5.Init.AutoReloadPreload = TIM_AUTORELOAD_PRELOAD_ENABLE;
  if (HAL_TIM_Base_Init(&htim5) != HAL_OK)
  {
    Error_Handler();
  }
  sClockSourceConfig.ClockSource = TIM_CLOCKSOURCE_INTERNAL;
  if (HAL_TIM_ConfigClockSource(&htim5, &sClockSourceConfig) != HAL_OK)
  {
    Error_Handler();
  }
  sMasterConfig.MasterOutputTrigger = TIM_TRGO_RESET;
  sMasterConfig.MasterSlaveMode = TIM_MASTERSLAVEMODE_DISABLE;
  if (HAL_TIMEx_MasterConfigSynchronization(&htim5, &sMasterConfig) != HAL_OK)
  {
    Error_Handler();
  }

}

static void MX_TIM6_Init(void)
{

  TIM_MasterConfigTypeDef sMasterConfig = {0};

  htim6.Instance = TIM6;
  htim6.Init.Prescaler = 240-1;
  htim6.Init.CounterMode = TIM_COUNTERMODE_UP;
  htim6.Init.Period = 1000-1;
  htim6.Init.AutoReloadPreload = TIM_AUTORELOAD_PRELOAD_DISABLE;
  if (HAL_TIM_Base_Init(&htim6) != HAL_OK)
  {
    Error_Handler();
  }
  sMasterConfig.MasterOutputTrigger = TIM_TRGO_RESET;
  sMasterConfig.MasterSlaveMode = TIM_MASTERSLAVEMODE_DISABLE;
  if (HAL_TIMEx_MasterConfigSynchronization(&htim6, &sMasterConfig) != HAL_OK)
  {
    Error_Handler();
  }

}

static void MX_TIM7_Init(void)
{

  TIM_MasterConfigTypeDef sMasterConfig = {0};

  htim7.Instance = TIM7;
  htim7.Init.Prescaler = 240-1;
  htim7.Init.CounterMode = TIM_COUNTERMODE_UP;
  htim7.Init.Period = 1000-1;
  htim7.Init.AutoReloadPreload = TIM_AUTORELOAD_PRELOAD_DISABLE;
  if (HAL_TIM_Base_Init(&htim7) != HAL_OK)
  {
    Error_Handler();
  }
  sMasterConfig.MasterOutputTrigger = TIM_TRGO_RESET;
  sMasterConfig.MasterSlaveMode = TIM_MASTERSLAVEMODE_DISABLE;
  if (HAL_TIMEx_MasterConfigSynchronization(&htim7, &sMasterConfig) != HAL_OK)
  {
    Error_Handler();
  }

}

static void MX_TIM13_Init(void)
{

  htim13.Instance = TIM13;
  htim13.Init.Prescaler = 240-1;
  htim13.Init.CounterMode = TIM_COUNTERMODE_UP;
  htim13.Init.Period = 1000-1;
  htim13.Init.ClockDivision = TIM_CLOCKDIVISION_DIV1;
  htim13.Init.AutoReloadPreload = TIM_AUTORELOAD_PRELOAD_DISABLE;
  if (HAL_TIM_Base_Init(&htim13) != HAL_OK)
  {
    Error_Handler();
  }

}

static void MX_UART4_Init(void)
{

  huart4.Instance = UART4;
  huart4.Init.BaudRate = 2500000;
  huart4.Init.WordLength = UART_WORDLENGTH_8B;
  huart4.Init.StopBits = UART_STOPBITS_1;
  huart4.Init.Parity = UART_PARITY_NONE;
  huart4.Init.Mode = UART_MODE_TX_RX;
  huart4.Init.HwFlowCtl = UART_HWCONTROL_NONE;
  huart4.Init.OverSampling = UART_OVERSAMPLING_16;
  huart4.Init.OneBitSampling = UART_ONE_BIT_SAMPLE_DISABLE;
  huart4.Init.ClockPrescaler = UART_PRESCALER_DIV1;
  huart4.AdvancedInit.AdvFeatureInit = UART_ADVFEATURE_NO_INIT;
  if (HAL_RS485Ex_Init(&huart4, UART_DE_POLARITY_HIGH, 0, 0) != HAL_OK)
  {
    Error_Handler();
  }
  if (HAL_UARTEx_SetTxFifoThreshold(&huart4, UART_TXFIFO_THRESHOLD_1_8) != HAL_OK)
  {
    Error_Handler();
  }
  if (HAL_UARTEx_SetRxFifoThreshold(&huart4, UART_RXFIFO_THRESHOLD_1_8) != HAL_OK)
  {
    Error_Handler();
  }
  if (HAL_UARTEx_DisableFifoMode(&huart4) != HAL_OK)
  {
    Error_Handler();
  }

}

static void MX_UART8_Init(void)
{

  huart8.Instance = UART8;
  huart8.Init.BaudRate = 2500000;
  huart8.Init.WordLength = UART_WORDLENGTH_8B;
  huart8.Init.StopBits = UART_STOPBITS_1;
  huart8.Init.Parity = UART_PARITY_NONE;
  huart8.Init.Mode = UART_MODE_TX_RX;
  huart8.Init.HwFlowCtl = UART_HWCONTROL_NONE;
  huart8.Init.OverSampling = UART_OVERSAMPLING_16;
  huart8.Init.OneBitSampling = UART_ONE_BIT_SAMPLE_DISABLE;
  huart8.Init.ClockPrescaler = UART_PRESCALER_DIV1;
  huart8.AdvancedInit.AdvFeatureInit = UART_ADVFEATURE_NO_INIT;
  if (HAL_RS485Ex_Init(&huart8, UART_DE_POLARITY_HIGH, 0, 0) != HAL_OK)
  {
    Error_Handler();
  }
  if (HAL_UARTEx_SetTxFifoThreshold(&huart8, UART_TXFIFO_THRESHOLD_1_8) != HAL_OK)
  {
    Error_Handler();
  }
  if (HAL_UARTEx_SetRxFifoThreshold(&huart8, UART_RXFIFO_THRESHOLD_1_8) != HAL_OK)
  {
    Error_Handler();
  }
  if (HAL_UARTEx_DisableFifoMode(&huart8) != HAL_OK)
  {
    Error_Handler();
  }

}

static void MX_USART1_Init(void)
{

  husart1.Instance = USART1;
  husart1.Init.BaudRate = 115200;
  husart1.Init.WordLength = USART_WORDLENGTH_8B;
  husart1.Init.StopBits = USART_STOPBITS_1;
  husart1.Init.Parity = USART_PARITY_NONE;
  husart1.Init.Mode = USART_MODE_TX_RX;
  husart1.Init.CLKPolarity = USART_POLARITY_LOW;
  husart1.Init.CLKPhase = USART_PHASE_1EDGE;
  husart1.Init.CLKLastBit = USART_LASTBIT_DISABLE;
  husart1.Init.ClockPrescaler = USART_PRESCALER_DIV1;
  husart1.SlaveMode = USART_SLAVEMODE_DISABLE;
  if (HAL_USART_Init(&husart1) != HAL_OK)
  {
    Error_Handler();
  }
  if (HAL_USARTEx_SetTxFifoThreshold(&husart1, USART_TXFIFO_THRESHOLD_1_8) != HAL_OK)
  {
    Error_Handler();
  }
  if (HAL_USARTEx_SetRxFifoThreshold(&husart1, USART_RXFIFO_THRESHOLD_1_8) != HAL_OK)
  {
    Error_Handler();
  }
  if (HAL_USARTEx_DisableFifoMode(&husart1) != HAL_OK)
  {
    Error_Handler();
  }

}

static void MX_USART2_UART_Init(void)
{

  huart2.Instance = USART2;
  huart2.Init.BaudRate = 921600;
  huart2.Init.WordLength = UART_WORDLENGTH_8B;
  huart2.Init.StopBits = UART_STOPBITS_1;
  huart2.Init.Parity = UART_PARITY_NONE;
  huart2.Init.Mode = UART_MODE_TX_RX;
  huart2.Init.HwFlowCtl = UART_HWCONTROL_NONE;
  huart2.Init.OverSampling = UART_OVERSAMPLING_16;
  huart2.Init.OneBitSampling = UART_ONE_BIT_SAMPLE_DISABLE;
  huart2.Init.ClockPrescaler = UART_PRESCALER_DIV1;
  huart2.AdvancedInit.AdvFeatureInit = UART_ADVFEATURE_NO_INIT;
  if (HAL_RS485Ex_Init(&huart2, UART_DE_POLARITY_HIGH, 0, 0) != HAL_OK)
  {
    Error_Handler();
  }
  if (HAL_UARTEx_SetTxFifoThreshold(&huart2, UART_TXFIFO_THRESHOLD_1_8) != HAL_OK)
  {
    Error_Handler();
  }
  if (HAL_UARTEx_SetRxFifoThreshold(&huart2, UART_RXFIFO_THRESHOLD_1_8) != HAL_OK)
  {
    Error_Handler();
  }
  if (HAL_UARTEx_DisableFifoMode(&huart2) != HAL_OK)
  {
    Error_Handler();
  }

}

static void MX_DMA_Init(void)
{

  /* DMA controller clock enable */
  __HAL_RCC_DMA1_CLK_ENABLE();
  __HAL_RCC_DMA2_CLK_ENABLE();

  /* DMA interrupt init */
  /* DMA1_Stream0_IRQn interrupt configuration */
  HAL_NVIC_SetPriority(DMA1_Stream0_IRQn, 1, 0);
  HAL_NVIC_EnableIRQ(DMA1_Stream0_IRQn);
  /* DMA1_Stream1_IRQn interrupt configuration */
  HAL_NVIC_SetPriority(DMA1_Stream1_IRQn, 1, 0);
  HAL_NVIC_EnableIRQ(DMA1_Stream1_IRQn);
  /* DMA1_Stream2_IRQn interrupt configuration */
  HAL_NVIC_SetPriority(DMA1_Stream2_IRQn, 1, 0);
  HAL_NVIC_EnableIRQ(DMA1_Stream2_IRQn);
  /* DMA1_Stream3_IRQn interrupt configuration */
  HAL_NVIC_SetPriority(DMA1_Stream3_IRQn, 1, 0);
  HAL_NVIC_EnableIRQ(DMA1_Stream3_IRQn);
  /* DMA1_Stream4_IRQn interrupt configuration */
  HAL_NVIC_SetPriority(DMA1_Stream4_IRQn, 7, 0);
  HAL_NVIC_EnableIRQ(DMA1_Stream4_IRQn);
  /* DMA1_Stream5_IRQn interrupt configuration */
  HAL_NVIC_SetPriority(DMA1_Stream5_IRQn, 7, 0);
  HAL_NVIC_EnableIRQ(DMA1_Stream5_IRQn);
  /* DMA2_Stream0_IRQn interrupt configuration */
  HAL_NVIC_SetPriority(DMA2_Stream0_IRQn, 1, 0);
  HAL_NVIC_EnableIRQ(DMA2_Stream0_IRQn);
  /* DMA2_Stream1_IRQn interrupt configuration */
  HAL_NVIC_SetPriority(DMA2_Stream1_IRQn, 1, 0);
  HAL_NVIC_EnableIRQ(DMA2_Stream1_IRQn);
  /* DMA2_Stream2_IRQn interrupt configuration */
  HAL_NVIC_SetPriority(DMA2_Stream2_IRQn, 1, 0);
  HAL_NVIC_EnableIRQ(DMA2_Stream2_IRQn);
  /* DMA2_Stream3_IRQn interrupt configuration */
  HAL_NVIC_SetPriority(DMA2_Stream3_IRQn, 1, 0);
  HAL_NVIC_EnableIRQ(DMA2_Stream3_IRQn);

}

static void MX_GPIO_Init(void)
{
  GPIO_InitTypeDef GPIO_InitStruct = {0};

  /* GPIO Ports Clock Enable */
  __HAL_RCC_GPIOE_CLK_ENABLE();
  __HAL_RCC_GPIOC_CLK_ENABLE();
  __HAL_RCC_GPIOH_CLK_ENABLE();
  __HAL_RCC_GPIOA_CLK_ENABLE();
  __HAL_RCC_GPIOB_CLK_ENABLE();
  __HAL_RCC_GPIOD_CLK_ENABLE();

  /*Configure GPIO pin Output Level */
  HAL_GPIO_WritePin(GPIOC, USER_IO5_Pin|USER_IO6_Pin|USER_IO7_Pin|DRV_EN_GATE_Pin, GPIO_PIN_RESET);

  /*Configure GPIO pin Output Level */
  HAL_GPIO_WritePin(GPIOD, DRV_AF_SPI_NSS_Pin|FLASH_AF_SPI_NSS_Pin|USER_SPI_NSS_Pin, GPIO_PIN_SET);

  /*Configure GPIO pin Output Level */
  HAL_GPIO_WritePin(GPIOB, LED_RED_Pin|LED_BLUE_Pin, GPIO_PIN_RESET);

  /*Configure GPIO pins : USER_IO1_Pin USER_IO2_Pin USER_IO3_Pin USER_IO4_Pin */
  GPIO_InitStruct.Pin = USER_IO1_Pin|USER_IO2_Pin|USER_IO3_Pin|USER_IO4_Pin;
  GPIO_InitStruct.Mode = GPIO_MODE_INPUT;
  GPIO_InitStruct.Pull = GPIO_PULLUP;
  HAL_GPIO_Init(GPIOE, &GPIO_InitStruct);

  /*Configure GPIO pins : USER_IO5_Pin USER_IO6_Pin USER_IO7_Pin */
  GPIO_InitStruct.Pin = USER_IO5_Pin|USER_IO6_Pin|USER_IO7_Pin;
  GPIO_InitStruct.Mode = GPIO_MODE_OUTPUT_PP;
  GPIO_InitStruct.Pull = GPIO_NOPULL;
  GPIO_InitStruct.Speed = GPIO_SPEED_FREQ_LOW;
  HAL_GPIO_Init(GPIOC, &GPIO_InitStruct);

  /*Configure GPIO pin : DRV_EN_GATE_Pin */
  GPIO_InitStruct.Pin = DRV_EN_GATE_Pin;
  GPIO_InitStruct.Mode = GPIO_MODE_OUTPUT_PP;
  GPIO_InitStruct.Pull = GPIO_NOPULL;
  GPIO_InitStruct.Speed = GPIO_SPEED_FREQ_VERY_HIGH;
  HAL_GPIO_Init(DRV_EN_GATE_GPIO_Port, &GPIO_InitStruct);

  /*Configure GPIO pins : ECAT_SYNC1_Pin ECAT_SYNC0_Pin ECAT_IRQ_Pin */
  GPIO_InitStruct.Pin = ECAT_SYNC1_Pin|ECAT_SYNC0_Pin|ECAT_IRQ_Pin;
  GPIO_InitStruct.Mode = GPIO_MODE_IT_FALLING;
  GPIO_InitStruct.Pull = GPIO_PULLUP;
  HAL_GPIO_Init(GPIOD, &GPIO_InitStruct);

  /*Configure GPIO pins : DRV_AF_SPI_NSS_Pin FLASH_AF_SPI_NSS_Pin USER_SPI_NSS_Pin */
  GPIO_InitStruct.Pin = DRV_AF_SPI_NSS_Pin|FLASH_AF_SPI_NSS_Pin|USER_SPI_NSS_Pin;
  GPIO_InitStruct.Mode = GPIO_MODE_OUTPUT_PP;
  GPIO_InitStruct.Pull = GPIO_PULLUP;
  GPIO_InitStruct.Speed = GPIO_SPEED_FREQ_VERY_HIGH;
  HAL_GPIO_Init(GPIOD, &GPIO_InitStruct);

  /*Configure GPIO pins : LED_RED_Pin LED_BLUE_Pin */
  GPIO_InitStruct.Pin = LED_RED_Pin|LED_BLUE_Pin;
  GPIO_InitStruct.Mode = GPIO_MODE_OUTPUT_PP;
  GPIO_InitStruct.Pull = GPIO_NOPULL;
  GPIO_InitStruct.Speed = GPIO_SPEED_FREQ_LOW;
  HAL_GPIO_Init(GPIOB, &GPIO_InitStruct);

  /* EXTI interrupt init*/
  HAL_NVIC_SetPriority(EXTI9_5_IRQn, 1, 0);
  HAL_NVIC_SetPriority(EXTI15_10_IRQn, 2, 0);

}

void Error_Handler(void)
{
  __disable_irq();
  while (1)
  {
  }
}
